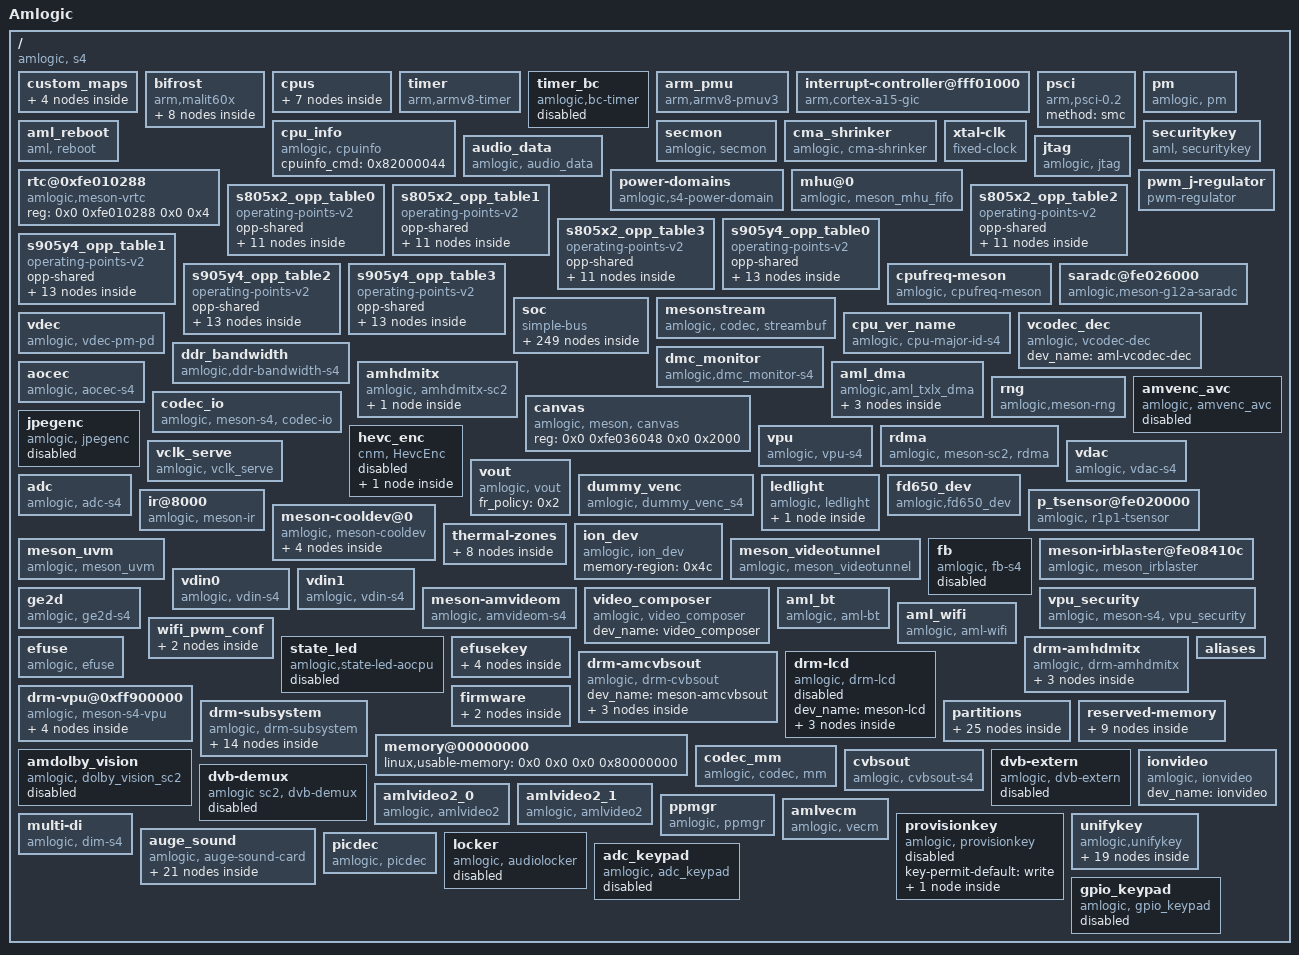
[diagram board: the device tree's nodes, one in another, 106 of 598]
/dts-v1/;

/ {
	model = "Amlogic";
	amlogic-dt-id = "s4_s905w2_2g";
	compatible = "amlogic, s4";
	interrupt-parent = <0x1>;
	#address-cells = <0x2>;
	#size-cells = <0x2>;

	custom_maps {
		mapnum = <0x4>;
		map0 = <0x2>;
		map1 = <0x3>;
		map2 = <0x4>;
		map3 = <0x5>;
		phandle = <0x46>;

		map_0 {
			mapname = "amlogic-remote-1";
			customcode = <0x4040>;
			release_delay = <0x50>;
			size = <0x18>;
			keymap = <0xb 0x10002 0x20003 0x30004 0x40005 0x50006 0x60007 0x70008 0x80009 0x9000a 0xb0067 0xe006c 0x100069 0x11006a 0xd0061 0x42009e 0x45008b 0x180073 0x170072 0x530077 0x4d0074 0x430071 0x1a0066 0x4700d9>;
			phandle = <0x2>;
		};

		map_1 {
			mapname = "amlogic-remote-2";
			customcode = <0xfe01>;
			release_delay = <0x50>;
			size = <0x35>;
			keymap = <0x10002 0x20003 0x30004 0x40005 0x50006 0x60007 0x70008 0x80009 0x9000a 0xa000b 0x1f01d2 0x15008b 0x16000f 0xc0192 0xd0193 0xe0073 0xf0072 0x110066 0x1c006a 0x1b0069 0x190067 0x1a006c 0x1d001c 0x170071 0x4900db 0x43009e 0x1201d5 0x1401d6 0x1801d7 0x590166 0x5a00a6 0x100074 0x4200a5 0x4400a3 0x1e00a8 0x4b00d0 0x5800a4 0x460082 0x400083 0x380046 0x5701d0 0x5b01d1 0x54018e 0x4c018f 0x4e0190 0x550191 0x5300ed 0x5200ee 0x3900d4 0x4100d5 0xb00d6 0xd8 0x1300d9>;
			phandle = <0x3>;
		};

		map_2 {
			mapname = "amlogic-remote-3";
			customcode = <0xbd02>;
			release_delay = <0x50>;
			size = <0x11>;
			keymap = <0xca0067 0xd2006c 0x990069 0xc1006a 0xce0061 0x450074 0xc50085 0x800071 0xd0000f 0xd6007d 0x950066 0xdd0068 0x8c006d 0x890083 0x9c0082 0x9a0078 0xcd0079>;
			phandle = <0x4>;
		};

		map_3 {
			mapname = "amlogic-remote-4";
			customcode = <0x7788>;
			release_delay = <0x50>;
			size = <0x26>;
			keymap = <0x10002 0x20003 0x30004 0x40005 0x50006 0x60007 0x70008 0x80009 0x9000a 0xa000b 0x5801d7 0x290166 0x74009c 0x4600d9 0xf008d 0x150067 0x16006c 0x170069 0x18006a 0x19001c 0x470066 0x48009e 0x32008a 0x210074 0x6001d2 0x250071 0x230073 0x240072 0x6300bb 0x6400bc 0x6700bd 0x6800be 0x330192 0x340193 0x4b018e 0x4a018f 0x490190 0x4c0191>;
			phandle = <0x5>;
		};
	};

	bifrost {
		compatible = "arm,malit60x", "arm,malit6xx", "arm,mali-midgard";
		#cooling-cells = <0x2>;
		reg = <0x0 0xfe400000 0x0 0x4000 0x0 0xfe002000 0x0 0x1000 0x0 0xff800000 0x0 0x1000 0x0 0xff63c000 0x0 0x1000 0x0 0xfe002000 0x0 0x1000>;
		interrupt-parent = <0x1>;
		interrupts = <0x0 0x90 0x4 0x0 0x91 0x4 0x0 0x92 0x4>;
		interrupt-names = "GPU", "MMU", "JOB";
		num_of_pp = <0x2>;
		sc_mpp = <0x1>;
		tbl = <0x6 0x7 0x8 0x9 0xa 0xa>;
		clk_cntl_reg = <0x57>;
		clocks = <0xb 0x91>;
		clock-names = "gpu_mux";
		assigned-clocks = <0xb 0x8b 0xb 0x8d 0xb 0x91>;
		assigned-clock-parents = <0xb 0xf 0x0 0xb 0x8d>;
		assigned-clock-rates = <0x0 0x1dcd6500 0x0>;
		phandle = <0x4b>;

		clk125_cfg {
			clk_freq = <0x7735940>;
			clk_parent = "fclk_div4";
			clkp_freq = <0x1dcd6500>;
			clk_reg = <0xa03>;
			voltage = <0x47e>;
			keep_count = <0x5>;
			threshold = <0x1e 0x78>;
		};

		dvfs250_cfg {
			clk_freq = <0xee6b280>;
			clk_parent = "fclk_div4";
			clkp_freq = <0x1dcd6500>;
			clk_reg = <0xa01>;
			voltage = <0x47e>;
			keep_count = <0x5>;
			threshold = <0x0 0x4c>;
		};

		dvfs285_cfg {
			clk_freq = <0x1107a76d>;
			clk_parent = "fclk_div7";
			clkp_freq = <0x1107a76d>;
			clk_reg = <0xe00>;
			voltage = <0x47e>;
			keep_count = <0x5>;
			threshold = <0x0 0x4c>;
			phandle = <0x6>;
		};

		dvfs400_cfg {
			clk_freq = <0x17d78400>;
			clk_parent = "fclk_div5";
			clkp_freq = <0x17d78400>;
			clk_reg = <0xc00>;
			voltage = <0x47e>;
			keep_count = <0x5>;
			threshold = <0x98 0xcf>;
			phandle = <0x7>;
		};

		dvfs500_cfg {
			clk_freq = <0x1dcd6500>;
			clk_parent = "fclk_div4";
			clkp_freq = <0x1dcd6500>;
			clk_reg = <0xa00>;
			voltage = <0x47e>;
			keep_count = <0x5>;
			threshold = <0x26 0xc2>;
			phandle = <0x8>;
		};

		dvfs666_cfg {
			clk_freq = <0x27bc86aa>;
			clk_parent = "fclk_div3";
			clkp_freq = <0x27bc86aa>;
			clk_reg = <0x800>;
			voltage = <0x47e>;
			keep_count = <0x5>;
			threshold = <0x96 0xcb>;
			phandle = <0x9>;
		};

		dvfs800_cfg {
			clk_freq = <0x2faf0800>;
			clk_parent = "fclk_div2p5";
			clkp_freq = <0x2faf0800>;
			clk_reg = <0x600>;
			voltage = <0x47e>;
			keep_count = <0x5>;
			threshold = <0xe6 0xff>;
			phandle = <0xa>;
		};

		dvfs850_cfg {
			clk_freq = <0x326cef80>;
			clk_parent = "gp0_pll";
			clkp_freq = <0x326cef80>;
			clk_reg = <0x200>;
			voltage = <0x47e>;
			keep_count = <0x5>;
			threshold = <0x9c 0xff>;
		};
	};

	cpus {
		#address-cells = <0x2>;
		#size-cells = <0x0>;

		cpu@0 {
			device_type = "cpu";
			compatible = "arm,cortex-a55", "arm,armv8";
			reg = <0x0 0x0>;
			enable-method = "psci";
			cpu-idle-states = <0xc 0xd>;
			dynamic-power-coefficient = <0xe6>;
			#cooling-cells = <0x2>;
			clocks = <0xb 0x1b 0xb 0x1a 0xb 0x3>;
			clock-names = "core_clk", "low_freq_clk_parent", "high_freq_clk_parent";
			cpu-supply = <0xe>;
			voltage-tolerance = <0x0>;
			clock-latency = <0xc350>;
			multi_tables_available;
			operating-points-v2 = <0xf 0x10 0x11 0x12>;
			phandle = <0x4a>;
		};

		cpu@1 {
			device_type = "cpu";
			compatible = "arm,cortex-a55", "arm,armv8";
			reg = <0x0 0x1>;
			enable-method = "psci";
			cpu-idle-states = <0xc 0xd>;
			dynamic-power-coefficient = <0xe6>;
			#cooling-cells = <0x2>;
			clocks = <0xb 0x1b 0xb 0x1a 0xb 0x3>;
			clock-names = "core_clk", "low_freq_clk_parent", "high_freq_clk_parent";
			cpu-supply = <0xe>;
			voltage-tolerance = <0x0>;
			clock-latency = <0xc350>;
			multi_tables_available;
			operating-points-v2 = <0xf 0x10 0x11 0x12>;
		};

		cpu@2 {
			device_type = "cpu";
			compatible = "arm,cortex-a55", "arm,armv8";
			reg = <0x0 0x2>;
			enable-method = "psci";
			cpu-idle-states = <0xc 0xd>;
			dynamic-power-coefficient = <0xe6>;
			#cooling-cells = <0x2>;
			clocks = <0xb 0x1b 0xb 0x1a 0xb 0x3>;
			clock-names = "core_clk", "low_freq_clk_parent", "high_freq_clk_parent";
			cpu-supply = <0xe>;
			voltage-tolerance = <0x0>;
			clock-latency = <0xc350>;
			multi_tables_available;
			operating-points-v2 = <0xf 0x10 0x11 0x12>;
		};

		cpu@3 {
			device_type = "cpu";
			compatible = "arm,cortex-a55", "arm,armv8";
			reg = <0x0 0x3>;
			enable-method = "psci";
			cpu-idle-states = <0xc 0xd>;
			dynamic-power-coefficient = <0xe6>;
			#cooling-cells = <0x2>;
			clocks = <0xb 0x1b 0xb 0x1a 0xb 0x3>;
			clock-names = "core_clk", "low_freq_clk_parent", "high_freq_clk_parent";
			cpu-supply = <0xe>;
			voltage-tolerance = <0x0>;
			clock-latency = <0xc350>;
			multi_tables_available;
			operating-points-v2 = <0xf 0x10 0x11 0x12>;
		};

		idle-states {
			entry-method = "arm,psci-0.2";

			cpu-sleep-0 {
				compatible = "arm,idle-state";
				arm,psci-suspend-param = <0x10000>;
				local-timer-stop;
				entry-latency-us = <0xfa0>;
				exit-latency-us = <0x1388>;
				min-residency-us = <0x2710>;
				phandle = <0xc>;
			};

			system-sleep-0 {
				compatible = "arm,idle-state";
				arm,psci-suspend-param = <0x0>;
				entry-latency-us = <0x3fffffff>;
				exit-latency-us = <0x40000000>;
				min-residency-us = <0xffffffff>;
				phandle = <0xd>;
			};
		};
	};

	timer {
		compatible = "arm,armv8-timer";
		interrupts = <0x1 0xd 0xff08 0x1 0xe 0xff08 0x1 0xb 0xff08 0x1 0xa 0xff08>;
	};

	timer_bc {
		compatible = "amlogic,bc-timer";
		status = "disabled";
		reg = <0x0 0xfe0100d8 0x0 0x4 0x0 0xfe0100dc 0x0 0x4>;
		timer_name = "Meson TimerD";
		clockevent-rating = <0x12c>;
		clockevent-shift = <0x14>;
		clockevent-features = <0x23>;
		interrupts = <0x0 0x3 0x1>;
		bit_enable = <0x7>;
		bit_mode = <0x6>;
		bit_resolution = <0x0>;
		resolution_1us = <0x1>;
		min_delta_ns = <0xa>;
	};

	arm_pmu {
		compatible = "arm,armv8-pmuv3";
		private-interrupts;
		interrupts = <0x0 0xe9 0x4 0x0 0xea 0x4 0x0 0xeb 0x4 0x0 0xec 0x4>;
		reg = <0x0 0xff634680 0x0 0x4>;
		cpumasks = <0xf>;
		relax-timer-ns = <0x989680>;
		max-wait-cnt = <0x2710>;
	};

	interrupt-controller@fff01000 {
		compatible = "arm,cortex-a15-gic", "arm,cortex-a9-gic";
		#interrupt-cells = <0x3>;
		#address-cells = <0x0>;
		interrupt-controller;
		reg = <0x0 0xfff01000 0x0 0x1000 0x0 0xfff02000 0x0 0x100>;
		interrupts = <0x1 0x9 0xf04>;
		phandle = <0x1>;
	};

	psci {
		compatible = "arm,psci-0.2";
		method = "smc";
	};

	pm {
		compatible = "amlogic, pm";
		status = "okay";
		device_name = "aml_pm";
		reg = <0x0 0xfe010288 0x0 0x4 0x0 0xfe0102dc 0x0 0x4>;
	};

	cpu_info {
		compatible = "amlogic, cpuinfo";
		status = "okay";
		cpuinfo_cmd = <0x82000044>;
	};

	aml_reboot {
		compatible = "aml, reboot";
		sys_reset = <0x84000009>;
		sys_poweroff = <0x84000008>;
		dis_nb_cpus_in_shutdown;
	};

	secmon {
		compatible = "amlogic, secmon";
		memory-region = <0x13>;
		in_base_func = <0x82000020>;
		out_base_func = <0x82000021>;
		reserve_mem_size = <0x3300000>;
	};

	cma_shrinker {
		compatible = "amlogic, cma-shrinker";
		status = "okay";
		adj = <0x0 0x64 0xc8 0xfa 0x384 0x3b6>;
		free = <0x1e00 0x5ee0 0x6f70 0x7f58 0x8000 0x8f10>;
	};

	securitykey {
		compatible = "aml, securitykey";
		storage_query = <0x82000060>;
		storage_read = <0x82000061>;
		storage_write = <0x82000062>;
		storage_tell = <0x82000063>;
		storage_verify = <0x82000064>;
		storage_status = <0x82000065>;
		storage_list = <0x82000067>;
		storage_remove = <0x82000068>;
		storage_in_func = <0x82000023>;
		storage_out_func = <0x82000024>;
		storage_block_func = <0x82000025>;
		storage_size_func = <0x82000027>;
		storage_set_enctype = <0x8200006a>;
		storage_get_enctype = <0x8200006b>;
		storage_version = <0x8200006c>;
	};

	xtal-clk {
		compatible = "fixed-clock";
		clock-frequency = <0x16e3600>;
		clock-output-names = "xtal";
		#clock-cells = <0x0>;
		phandle = <0x18>;
	};

	rtc@0xfe010288 {
		compatible = "amlogic,meson-vrtc";
		reg = <0x0 0xfe010288 0x0 0x4>;
	};

	audio_data {
		compatible = "amlogic, audio_data";
		mem_in_base_cmd = <0x82000020>;
		query_licence_cmd = <0x82000050>;
		status = "okay";
	};

	power-domains {
		compatible = "amlogic,s4-power-domain";
		#power-domain-cells = <0x1>;
		status = "okay";
		phandle = <0x25>;
	};

	jtag {
		compatible = "amlogic, jtag";
		status = "okay";
		select = "disable";
		pinctrl-names = "jtag_a_pins", "jtag_b_pins";
		pinctrl-0 = <0x14>;
		pinctrl-1 = <0x15>;
	};

	mhu@0 {
		status = "okay";
		compatible = "amlogic, meson_mhu_fifo";
		reg = <0x0 0xfe006000 0x0 0x800 0x0 0xfe006800 0x0 0x800 0x0 0xfe0070c0 0x0 0x40 0x0 0xfe007100 0x0 0x40 0x0 0xfe007140 0x0 0x40 0x0 0xfe007020 0x0 0x40>;
		interrupts = <0x0 0xf8 0x1>;
		mbox-irqctlr = <0x0>;
		mbox-nums = <0x2>;
		mbox-names = "ao_dev", "ap_to_ao";
		mboxes = <0x16 0x0 0x16 0x1>;
		mbox-id = <0x2 0x3>;
		#mbox-cells = <0x1>;
		phandle = <0x16>;
	};

	pwm_j-regulator {
		compatible = "pwm-regulator";
		pwms = <0x17 0x1 0x5dc 0x0>;
		regulator-name = "vddcpu0";
		regulator-min-microvolt = <0xa8368>;
		regulator-max-microvolt = <0x1001a8>;
		regulator-always-on;
		max-duty-cycle = <0x5dc>;
		voltage-table = <0x1001a8 0x0 0xfda98 0x3 0xfb388 0x6 0xf8c78 0x9 0xf6568 0xc 0xf3e58 0xe 0xf1748 0x11 0xef038 0x14 0xec928 0x17 0xea218 0x1a 0xe7b08 0x1d 0xe53f8 0x1f 0xe2ce8 0x22 0xe05d8 0x25 0xddec8 0x28 0xdb7b8 0x2b 0xd90a8 0x2d 0xd6998 0x30 0xd4288 0x33 0xd1b78 0x36 0xcf468 0x38 0xccd58 0x3b 0xca648 0x3e 0xc7f38 0x41 0xc5828 0x44 0xc3118 0x46 0xc0a08 0x49 0xbe2f8 0x4c 0xbbbe8 0x4f 0xb94d8 0x51 0xb6dc8 0x54 0xb46b8 0x57 0xb1fa8 0x59 0xaf898 0x5c 0xad188 0x5f 0xaaa78 0x62 0xa8368 0x64>;
		status = "okay";
		phandle = <0xe>;
	};

	s805x2_opp_table0 {
		compatible = "operating-points-v2";
		status = "okay";
		opp-shared;
		phandle = <0xf>;

		opp00 {
			opp-hz = <0x0 0x5f5e100>;
			opp-microvolt = <0xbbbe8>;
		};

		opp01 {
			opp-hz = <0x0 0xee6b280>;
			opp-microvolt = <0xbbbe8>;
		};

		opp02 {
			opp-hz = <0x0 0x1dcd6500>;
			opp-microvolt = <0xbbbe8>;
		};

		opp03 {
			opp-hz = <0x0 0x27b25a80>;
			opp-microvolt = <0xbbbe8>;
		};

		opp04 {
			opp-hz = <0x0 0x3b9aca00>;
			opp-microvolt = <0xbbbe8>;
		};

		opp05 {
			opp-hz = <0x0 0x47868c00>;
			opp-microvolt = <0xbbbe8>;
		};

		opp06 {
			opp-hz = <0x0 0x53af5700>;
			opp-microvolt = <0xc3118>;
		};

		opp07 {
			opp-hz = <0x0 0x59682f00>;
			opp-microvolt = <0xca648>;
		};

		opp08 {
			opp-hz = <0x0 0x5fd82200>;
			opp-microvolt = <0xd4288>;
		};

		opp09 {
			opp-hz = <0x0 0x6590fa00>;
			opp-microvolt = <0xddec8>;
		};

		opp10 {
			opp-hz = <0x0 0x6b49d200>;
			opp-microvolt = <0xf6568>;
		};
	};

	s805x2_opp_table1 {
		compatible = "operating-points-v2";
		status = "okay";
		opp-shared;
		phandle = <0x10>;

		opp00 {
			opp-hz = <0x0 0x5f5e100>;
			opp-microvolt = <0xbbbe8>;
		};

		opp01 {
			opp-hz = <0x0 0xee6b280>;
			opp-microvolt = <0xbbbe8>;
		};

		opp02 {
			opp-hz = <0x0 0x1dcd6500>;
			opp-microvolt = <0xbbbe8>;
		};

		opp03 {
			opp-hz = <0x0 0x27b25a80>;
			opp-microvolt = <0xbbbe8>;
		};

		opp04 {
			opp-hz = <0x0 0x3b9aca00>;
			opp-microvolt = <0xbbbe8>;
		};

		opp05 {
			opp-hz = <0x0 0x47868c00>;
			opp-microvolt = <0xbbbe8>;
		};

		opp06 {
			opp-hz = <0x0 0x53af5700>;
			opp-microvolt = <0xc3118>;
		};

		opp07 {
			opp-hz = <0x0 0x59682f00>;
			opp-microvolt = <0xca648>;
		};

		opp08 {
			opp-hz = <0x0 0x5fd82200>;
			opp-microvolt = <0xd4288>;
		};

		opp09 {
			opp-hz = <0x0 0x6590fa00>;
			opp-microvolt = <0xddec8>;
		};

		opp10 {
			opp-hz = <0x0 0x6b49d200>;
			opp-microvolt = <0xf6568>;
		};
	};

	s805x2_opp_table2 {
		compatible = "operating-points-v2";
		status = "okay";
		opp-shared;
		phandle = <0x11>;

		opp00 {
			opp-hz = <0x0 0x5f5e100>;
			opp-microvolt = <0xb94d8>;
		};

		opp01 {
			opp-hz = <0x0 0xee6b280>;
			opp-microvolt = <0xb94d8>;
		};

		opp02 {
			opp-hz = <0x0 0x1dcd6500>;
			opp-microvolt = <0xb94d8>;
		};

		opp03 {
			opp-hz = <0x0 0x27b25a80>;
			opp-microvolt = <0xb94d8>;
		};

		opp04 {
			opp-hz = <0x0 0x3b9aca00>;
			opp-microvolt = <0xb94d8>;
		};

		opp05 {
			opp-hz = <0x0 0x47868c00>;
			opp-microvolt = <0xb94d8>;
		};

		opp06 {
			opp-hz = <0x0 0x53af5700>;
			opp-microvolt = <0xb94d8>;
		};

		opp07 {
			opp-hz = <0x0 0x59682f00>;
			opp-microvolt = <0xbbbe8>;
		};

		opp08 {
			opp-hz = <0x0 0x5fd82200>;
			opp-microvolt = <0xc3118>;
		};

		opp09 {
			opp-hz = <0x0 0x6590fa00>;
			opp-microvolt = <0xca648>;
		};

		opp10 {
			opp-hz = <0x0 0x6b49d200>;
			opp-microvolt = <0xf3e58>;
		};
	};

	s805x2_opp_table3 {
		compatible = "operating-points-v2";
		status = "okay";
		opp-shared;
		phandle = <0x12>;

		opp00 {
			opp-hz = <0x0 0x5f5e100>;
			opp-microvolt = <0xb94d8>;
		};

		opp01 {
			opp-hz = <0x0 0xee6b280>;
			opp-microvolt = <0xb94d8>;
		};

		opp02 {
			opp-hz = <0x0 0x1dcd6500>;
			opp-microvolt = <0xb94d8>;
		};

		opp03 {
			opp-hz = <0x0 0x27b25a80>;
			opp-microvolt = <0xb94d8>;
		};

		opp04 {
			opp-hz = <0x0 0x3b9aca00>;
			opp-microvolt = <0xb94d8>;
		};

		opp05 {
			opp-hz = <0x0 0x47868c00>;
			opp-microvolt = <0xb94d8>;
		};

		opp06 {
			opp-hz = <0x0 0x53af5700>;
			opp-microvolt = <0xb94d8>;
		};

		opp07 {
			opp-hz = <0x0 0x59682f00>;
			opp-microvolt = <0xb94d8>;
		};

		opp08 {
			opp-hz = <0x0 0x5fd82200>;
			opp-microvolt = <0xbbbe8>;
		};

		opp09 {
			opp-hz = <0x0 0x6590fa00>;
			opp-microvolt = <0xc5828>;
		};

		opp10 {
			opp-hz = <0x0 0x6b49d200>;
			opp-microvolt = <0xe53f8>;
		};
	};

	s905y4_opp_table0 {
		compatible = "operating-points-v2";
		status = "okay";
		opp-shared;

		opp00 {
			opp-hz = <0x0 0x5f5e100>;
			opp-microvolt = <0xbbbe8>;
		};

		opp01 {
			opp-hz = <0x0 0xee6b280>;
			opp-microvolt = <0xbbbe8>;
		};

		opp02 {
			opp-hz = <0x0 0x1dcd6500>;
			opp-microvolt = <0xbbbe8>;
		};

		opp03 {
			opp-hz = <0x0 0x27b25a80>;
			opp-microvolt = <0xbbbe8>;
		};

		opp04 {
			opp-hz = <0x0 0x3b9aca00>;
			opp-microvolt = <0xbbbe8>;
		};

		opp05 {
			opp-hz = <0x0 0x47868c00>;
			opp-microvolt = <0xbbbe8>;
		};

		opp06 {
			opp-hz = <0x0 0x53af5700>;
			opp-microvolt = <0xc3118>;
		};

		opp07 {
			opp-hz = <0x0 0x59682f00>;
			opp-microvolt = <0xca648>;
		};

		opp08 {
			opp-hz = <0x0 0x5fd82200>;
			opp-microvolt = <0xd4288>;
		};

		opp09 {
			opp-hz = <0x0 0x6590fa00>;
			opp-microvolt = <0xddec8>;
		};

		opp10 {
			opp-hz = <0x0 0x6b49d200>;
			opp-microvolt = <0xea218>;
		};

		opp11 {
			opp-hz = <0x0 0x71b9c500>;
			opp-microvolt = <0xef038>;
		};

		opp12 {
			opp-hz = <0x0 0x77729d00>;
			opp-microvolt = <0xf6568>;
		};
	};

	s905y4_opp_table1 {
		compatible = "operating-points-v2";
		status = "okay";
		opp-shared;

		opp00 {
			opp-hz = <0x0 0x5f5e100>;
			opp-microvolt = <0xbbbe8>;
		};

		opp01 {
			opp-hz = <0x0 0xee6b280>;
			opp-microvolt = <0xbbbe8>;
		};

		opp02 {
			opp-hz = <0x0 0x1dcd6500>;
			opp-microvolt = <0xbbbe8>;
		};

		opp03 {
			opp-hz = <0x0 0x27b25a80>;
			opp-microvolt = <0xbbbe8>;
		};

		opp04 {
			opp-hz = <0x0 0x3b9aca00>;
			opp-microvolt = <0xbbbe8>;
		};

		opp05 {
			opp-hz = <0x0 0x47868c00>;
			opp-microvolt = <0xbbbe8>;
		};

		opp06 {
			opp-hz = <0x0 0x53af5700>;
			opp-microvolt = <0xc3118>;
		};

		opp07 {
			opp-hz = <0x0 0x59682f00>;
			opp-microvolt = <0xca648>;
		};

		opp08 {
			opp-hz = <0x0 0x5fd82200>;
			opp-microvolt = <0xd4288>;
		};

		opp09 {
			opp-hz = <0x0 0x6590fa00>;
			opp-microvolt = <0xddec8>;
		};

		opp10 {
			opp-hz = <0x0 0x6b49d200>;
			opp-microvolt = <0xea218>;
		};

		opp11 {
			opp-hz = <0x0 0x71b9c500>;
			opp-microvolt = <0xef038>;
		};

		opp12 {
			opp-hz = <0x0 0x77729d00>;
			opp-microvolt = <0xf6568>;
		};
	};

	s905y4_opp_table2 {
		compatible = "operating-points-v2";
		status = "okay";
		opp-shared;

		opp00 {
			opp-hz = <0x0 0x5f5e100>;
			opp-microvolt = <0xb94d8>;
		};

		opp01 {
			opp-hz = <0x0 0xee6b280>;
			opp-microvolt = <0xb94d8>;
		};

		opp02 {
			opp-hz = <0x0 0x1dcd6500>;
			opp-microvolt = <0xb94d8>;
		};

		opp03 {
			opp-hz = <0x0 0x27b25a80>;
			opp-microvolt = <0xb94d8>;
		};

		opp04 {
			opp-hz = <0x0 0x3b9aca00>;
			opp-microvolt = <0xb94d8>;
		};

		opp05 {
			opp-hz = <0x0 0x47868c00>;
			opp-microvolt = <0xb94d8>;
		};

		opp06 {
			opp-hz = <0x0 0x53af5700>;
			opp-microvolt = <0xb94d8>;
		};

		opp07 {
			opp-hz = <0x0 0x59682f00>;
			opp-microvolt = <0xbbbe8>;
		};

		opp08 {
			opp-hz = <0x0 0x5fd82200>;
			opp-microvolt = <0xc3118>;
		};

		opp09 {
			opp-hz = <0x0 0x6590fa00>;
			opp-microvolt = <0xca648>;
		};

		opp10 {
			opp-hz = <0x0 0x6b49d200>;
			opp-microvolt = <0xe2ce8>;
		};

		opp11 {
			opp-hz = <0x0 0x71b9c500>;
			opp-microvolt = <0xea218>;
		};

		opp12 {
			opp-hz = <0x0 0x77729d00>;
			opp-microvolt = <0xf3e58>;
		};
	};

	s905y4_opp_table3 {
		compatible = "operating-points-v2";
		status = "okay";
		opp-shared;

		opp00 {
			opp-hz = <0x0 0x5f5e100>;
			opp-microvolt = <0xb94d8>;
		};

		opp01 {
			opp-hz = <0x0 0xee6b280>;
			opp-microvolt = <0xb94d8>;
		};

		opp02 {
			opp-hz = <0x0 0x1dcd6500>;
			opp-microvolt = <0xb94d8>;
		};

		opp03 {
			opp-hz = <0x0 0x27b25a80>;
			opp-microvolt = <0xb94d8>;
		};

		opp04 {
			opp-hz = <0x0 0x3b9aca00>;
			opp-microvolt = <0xb94d8>;
		};

		opp05 {
			opp-hz = <0x0 0x47868c00>;
			opp-microvolt = <0xb94d8>;
		};

		opp06 {
			opp-hz = <0x0 0x53af5700>;
			opp-microvolt = <0xb94d8>;
		};

		opp07 {
			opp-hz = <0x0 0x59682f00>;
			opp-microvolt = <0xb94d8>;
		};

		opp08 {
			opp-hz = <0x0 0x5fd82200>;
			opp-microvolt = <0xbbbe8>;
		};

		opp09 {
			opp-hz = <0x0 0x6590fa00>;
			opp-microvolt = <0xc5828>;
		};

		opp10 {
			opp-hz = <0x0 0x6b49d200>;
			opp-microvolt = <0xd90a8>;
		};

		opp11 {
			opp-hz = <0x0 0x71b9c500>;
			opp-microvolt = <0xddec8>;
		};

		opp12 {
			opp-hz = <0x0 0x77729d00>;
			opp-microvolt = <0xe53f8>;
		};
	};

	cpufreq-meson {
		compatible = "amlogic, cpufreq-meson";
		status = "okay";
	};

	saradc@fe026000 {
		compatible = "amlogic,meson-g12a-saradc", "amlogic,meson-saradc";
		status = "okay";
		#io-channel-cells = <0x1>;
		clocks = <0x18 0xb 0x136 0xb 0x104 0xb 0x102>;
		clock-names = "clkin", "core", "adc_clk", "adc_sel";
		interrupts = <0x0 0xb5 0x1>;
		reg = <0x0 0xfe026000 0x0 0x48>;
		phandle = <0xa1>;
	};

	soc {
		compatible = "simple-bus";
		#address-cells = <0x2>;
		#size-cells = <0x2>;
		ranges;

		apb4@fe000000 {
			compatible = "simple-bus";
			reg = <0x0 0xfe000000 0x0 0x480000>;
			#address-cells = <0x2>;
			#size-cells = <0x2>;
			ranges = <0x0 0x0 0x0 0xfe000000 0x0 0x480000>;

			clock-controller {
				compatible = "amlogic,s4-clkc";
				#clock-cells = <0x1>;
				reg = <0x0 0x0 0x0 0x49c 0x0 0x8000 0x0 0x348 0x0 0xe140 0x0 0x24>;
				reg-names = "basic", "pll", "cpu_clk";
				clocks = <0x18>;
				clock-names = "xtal";
				status = "okay";
				phandle = <0xb>;
			};

			meson_clk_msr@48000 {
				compatible = "amlogic,meson-s4-clk-measure";
				reg = <0x0 0x48000 0x0 0x1c>;
			};

			watchdog@2100 {
				compatible = "amlogic,meson-sc2-wdt";
				status = "okay";
				amlogic,feed_watchdog_mode = <0x1>;
				reg = <0x0 0x2100 0x0 0x10>;
				clocks = <0x18>;
			};

			pinctrl@4000 {
				compatible = "amlogic,meson-s4-periphs-pinctrl";
				#address-cells = <0x2>;
				#size-cells = <0x2>;
				ranges;
				phandle = <0x19>;

				bank@4000 {
					reg = <0x0 0x4000 0x0 0x4c 0x0 0x40c0 0x0 0x220>;
					reg-names = "mux", "gpio";
					gpio-controller;
					#gpio-cells = <0x2>;
					gpio-ranges = <0x19 0x0 0x0 0x52>;
					phandle = <0x1b>;
				};

				i2c0_pins1 {

					mux {
						groups = "i2c0_sda", "i2c0_scl";
						function = "i2c0";
						drive-strength-microamp = <0xbb8>;
						bias-disable;
					};
				};

				i2c1_pins1 {

					mux {
						groups = "i2c1_sda_c", "i2c1_scl_c";
						function = "i2c1";
						drive-strength-microamp = <0xbb8>;
						bias-disable;
					};
				};

				i2c1_pins2 {
					phandle = <0x1e>;

					mux {
						groups = "i2c1_sda_d", "i2c1_scl_d";
						function = "i2c1";
						drive-strength-microamp = <0xbb8>;
						bias-disable;
					};
				};

				i2c1_pins3 {

					mux {
						groups = "i2c1_sda_h", "i2c1_scl_h";
						function = "i2c1";
						drive-strength-microamp = <0xbb8>;
						bias-disable;
					};
				};

				i2c1_pins4 {

					mux {
						groups = "i2c1_sda_x", "i2c1_scl_x";
						function = "i2c1";
						drive-strength-microamp = <0xbb8>;
						bias-disable;
					};
				};

				i2c2_pins1 {

					mux {
						groups = "i2c2_sda_d", "i2c2_scl_d";
						function = "i2c2";
						drive-strength-microamp = <0xbb8>;
						bias-disable;
					};
				};

				i2c2_pins2 {

					mux {
						groups = "i2c2_sda_h8", "i2c2_scl_h9";
						function = "i2c2";
						drive-strength-microamp = <0xbb8>;
						bias-disable;
					};
				};

				i2c2_pins3 {

					mux {
						groups = "i2c2_sda_h0", "i2c2_scl_h1";
						function = "i2c2";
						drive-strength-microamp = <0xbb8>;
						bias-disable;
					};
				};

				i2c3_pins1 {

					mux {
						groups = "i2c3_sda_x", "i2c3_scl_x";
						function = "i2c3";
						drive-strength-microamp = <0xbb8>;
						bias-disable;
					};
				};

				i2c3_pins2 {
					phandle = <0x1f>;

					mux {
						groups = "i2c3_sda_z", "i2c3_scl_z";
						function = "i2c3";
						drive-strength-microamp = <0xbb8>;
						bias-disable;
					};
				};

				i2c4_pins1 {

					mux {
						groups = "i2c4_sda_c", "i2c4_scl_c";
						function = "i2c4";
						drive-strength-microamp = <0xbb8>;
						bias-disable;
					};
				};

				i2c4_pins2 {

					mux {
						groups = "i2c4_sda_d", "i2c4_scl_d";
						function = "i2c4";
						drive-strength-microamp = <0xbb8>;
						bias-disable;
					};
				};

				i2c4_pins3 {
					phandle = <0x20>;

					mux {
						groups = "i2c4_sda_z", "i2c4_scl_z";
						function = "i2c4";
						drive-strength-microamp = <0xbb8>;
						bias-disable;
					};
				};

				a_uart {
					phandle = <0x3c>;

					mux {
						groups = "uart_a_tx", "uart_a_rx", "uart_a_cts", "uart_a_rts";
						function = "uart_a";
					};
				};

				c_uart {
					phandle = <0x3d>;

					mux {
						groups = "uart_c_tx", "uart_c_rx";
						function = "uart_c";
					};
				};

				d_uart1 {
					phandle = <0x3e>;

					mux {
						groups = "uart_d_tx_h", "uart_d_rx_h";
						function = "uart_d";
					};
				};

				d_uart2 {

					mux {
						groups = "uart_d_tx_z", "uart_d_rx_z";
						function = "uart_d";
					};
				};

				e_uart1 {
					phandle = <0x3f>;

					mux {
						groups = "uart_e_tx_h", "uart_e_rx_h";
						function = "uart_e";
					};
				};

				e_uart2 {

					mux {
						groups = "uart_e_tx_z11", "uart_e_rx_z12";
						function = "uart_e";
					};
				};

				e_uart3 {

					mux {
						groups = "uart_e_tx_z8", "uart_e_rx_z9";
						function = "uart_e";
					};
				};

				emmc_pins {
					phandle = <0x2e>;

					mux-0 {
						groups = "emmc_nand_d0", "emmc_nand_d1", "emmc_nand_d2", "emmc_nand_d3", "emmc_nand_d4", "emmc_nand_d5", "emmc_nand_d6", "emmc_nand_d7", "emmc_cmd";
						function = "emmc";
						bias-pull-up;
						drive-strength-microamp = <0xfa0>;
					};

					mux-1 {
						groups = "emmc_clk";
						function = "emmc";
						bias-pull-up;
						drive-strength-microamp = <0xfa0>;
					};
				};

				emmc_ds_pins {
					phandle = <0x2f>;

					mux {
						groups = "emmc_nand_ds";
						function = "emmc";
						bias-pull-down;
						drive-strength-microamp = <0xfa0>;
					};
				};

				emmc_clk_gate_pins {
					phandle = <0x30>;

					mux {
						groups = "GPIOB_8";
						function = "gpio_periphs";
						bias-pull-down;
						drive-strength-microamp = <0xfa0>;
					};
				};

				all_nand_pins {
					phandle = <0x39>;

					mux {
						groups = "emmc_nand_d0", "emmc_nand_d1", "emmc_nand_d2", "emmc_nand_d3", "emmc_nand_d4", "emmc_nand_d5", "emmc_nand_d6", "emmc_nand_d7", "nand_ce0", "nand_ale", "nand_cle", "nand_wen_clk", "nand_ren_wr";
						function = "nand";
						input-enable;
					};
				};

				nand_cs {
					phandle = <0x3a>;

					mux {
						groups = "nand_ce0";
						function = "nand";
					};
				};

				sd_to_ao_uart_clr_pins {
					phandle = <0x34>;

					mux {
						groups = "GPIOD_0", "GPIOD_1";
						function = "gpio_periphs";
					};
				};

				sdcard_pins {
					phandle = <0x31>;

					mux {
						groups = "sdcard_d0_c", "sdcard_d1_c", "sdcard_d2_c", "sdcard_d3_c", "sdcard_clk_c", "sdcard_cmd_c";
						function = "sdcard";
						bias-pull-up;
						drive-strength-microamp = <0xfa0>;
					};
				};

				ao_to_sd_uart_pins {
					phandle = <0x35>;

					mux {
						groups = "uart_b_tx_c", "uart_b_rx_c";
						function = "uart_b";
						bias-pull-up;
						input-enable;
					};
				};

				ao_uart_pins {
					phandle = <0x36>;

					mux {
						groups = "uart_b_tx_d", "uart_b_rx_d";
						function = "uart_b";
						bias-pull-up;
						input-enable;
					};
				};

				sd_clr_all_pins {

					mux {
						groups = "GPIOC_0", "GPIOC_1", "GPIOC_2", "GPIOC_3", "GPIOC_5";
						function = "gpio_periphs";
						output-high;
					};

					mux1 {
						groups = "GPIOC_4";
						function = "gpio_periphs";
						output-low;
					};
				};

				sd_clr_noall_pins {

					mux {
						groups = "GPIOC_0", "GPIOC_1", "GPIOC_4", "GPIOC_5";
						function = "gpio_periphs";
						output-high;
					};
				};

				sd_1bit_pins {
					phandle = <0x33>;

					mux {
						groups = "sdcard_d0_c", "sdcard_clk_c", "sdcard_cmd_c";
						function = "sdcard";
						bias-pull-up;
						drive-strength-microamp = <0xfa0>;
					};
				};

				sdcard_clk_gate_pins {
					phandle = <0x32>;

					mux {
						groups = "GPIOC_4";
						function = "gpio_periphs";
						bias-pull-down;
						drive-strength-microamp = <0xfa0>;
					};
				};

				sd_iso7816_pins {

					mux {
						groups = "iso7816_clk_h", "iso7816_data_h";
						function = "iso7816";
						input-enable;
						bias-pull-down;
					};
				};

				sdio_pins {
					phandle = <0x37>;

					mux {
						groups = "sdio_d0", "sdio_d1", "sdio_d2", "sdio_d3", "sdio_clk", "sdio_cmd";
						function = "sdio";
						bias-pull-up;
						drive-strength-microamp = <0xfa0>;
					};
				};

				sdio_clk_gate_pins {
					phandle = <0x38>;

					mux {
						groups = "GPIOX_4";
						function = "gpio_periphs";
						bias-pull-down;
						drive-strength-microamp = <0xfa0>;
					};
				};

				hdmitx_hpd {
					phandle = <0x41>;

					mux {
						groups = "hdmitx_hpd_in";
						function = "hdmitx";
						bias-disable;
					};
				};

				hdmitx_hpd_gpio {

					mux {
						groups = "GPIOH_1";
						function = "gpio_periphs";
						bias-disable;
					};
				};

				hdmitx_ddc {
					phandle = <0x42>;

					mux {
						groups = "hdmitx_sda", "hdmitx_sck";
						function = "hdmitx";
						bias-disable;
						drive-strength = <0x3>;
					};
				};

				dtvdemod_if_agc_pins {

					mux {
						groups = "dtv_a_if_agc_z6", "dtv_b_if_agc";
						function = "dtv";
					};
				};

				ee_ceca {
					phandle = <0x43>;

					mux {
						groups = "ao_cec_a";
						function = "ao_cec_a";
					};
				};

				ee_cecb {
					phandle = <0x44>;

					mux {
						groups = "ao_cec_b";
						function = "ao_cec_b";
					};
				};

				jtag_a_pin {
					phandle = <0x14>;

					mux {
						groups = "jtag_1_tdi", "jtag_1_tdo", "jtag_1_clk", "jtag_1_tms";
						function = "jtag_1";
					};
				};

				jtag_b_pin {
					phandle = <0x15>;

					mux {
						groups = "jtag_2_tdi", "jtag_2_tdo", "jtag_2_clk", "jtag_2_tms";
						function = "jtag_2";
					};
				};

				pwm_a_pins {

					mux {
						groups = "pwm_a_d";
						function = "pwm_a";
					};
				};

				pwm_b_pins1 {

					mux {
						groups = "pwm_b_d";
						function = "pwm_b";
					};
				};

				pwm_b_pins2 {

					mux {
						groups = "pwm_b_x";
						function = "pwm_b";
					};
				};

				pwm_c_pins1 {

					mux {
						groups = "pwm_c_d";
						function = "pwm_c";
					};
				};

				pwm_c_pins2 {

					mux {
						groups = "pwm_c_x";
						function = "pwm_c";
					};
				};

				pwm_d_pins1 {

					mux {
						groups = "pwm_d_d";
						function = "pwm_d";
					};
				};

				pwm_d_pins2 {

					mux {
						groups = "pwm_d_h";
						function = "pwm_d";
					};
				};

				pwm_e_pins1 {
					phandle = <0x1d>;

					mux {
						groups = "pwm_e_x";
						function = "pwm_e";
						drive-strength-microamp = <0x1f4>;
					};
				};

				pwm_e_pins2 {

					mux {
						groups = "pwm_e_z";
						function = "pwm_e";
					};
				};

				pwm_f_pins1 {

					mux {
						groups = "pwm_f_x";
						function = "pwm_f";
					};
				};

				pwm_f_pins2 {

					mux {
						groups = "pwm_f_z";
						function = "pwm_f";
					};
				};

				pwm_g_pins1 {

					mux {
						groups = "pwm_g_d";
						function = "pwm_g";
					};
				};

				pwm_g_pins2 {

					mux {
						groups = "pwm_g_z";
						function = "pwm_g";
					};
				};

				pwm_h_pins {

					mux {
						groups = "pwm_h";
						function = "pwm_h";
					};
				};

				pwm_i_pins1 {

					mux {
						groups = "pwm_i_d";
						function = "pwm_i";
					};
				};

				pwm_i_pins2 {

					mux {
						groups = "pwm_i_h";
						function = "pwm_i";
					};
				};

				pwm_j_pins {

					mux {
						groups = "pwm_j";
						function = "pwm_j";
					};
				};

				pwm_a_hiz_pins {

					mux {
						groups = "pwm_a_hiz";
						function = "pwm_a_hiz";
					};
				};

				pwm_b_hiz_pins {

					mux {
						groups = "pwm_b_hiz";
						function = "pwm_b_hiz";
					};
				};

				pwm_c_hiz_pins {

					mux {
						groups = "pwm_c_hiz";
						function = "pwm_b_hiz";
					};
				};

				pwm_g_hiz_pins {

					mux {
						groups = "pwm_g_hiz";
						function = "pwm_g_hiz";
					};
				};

				remote_pin {
					phandle = <0x47>;

					mux {
						groups = "remote_in";
						function = "remote_in";
						bias-disable;
					};
				};

				spicc0_pins_x {
					phandle = <0x1a>;

					mux {
						groups = "spi_a_mosi_x", "spi_a_miso_x", "spi_a_clk_x";
						function = "spi_a";
						drive-strength = <0x2>;
					};
				};

				spicc0_pins_h {

					mux {
						groups = "spi_a_mosi_h", "spi_a_miso_h", "spi_a_clk_h";
						function = "spi_a";
						drive-strength = <0x2>;
					};
				};

				spicc0_pins_z {

					mux {
						groups = "spi_a_mosi_z", "spi_a_miso_z", "spi_a_clk_z";
						function = "spi_a";
						drive-strength = <0x2>;
					};
				};

				spifc_pins {
					phandle = <0x1c>;

					mux {
						groups = "spif_hold", "spif_mo", "spif_mi", "spif_clk", "spif_wp", "spif_cs";
						function = "spif";
						drive-strength-microamp = <0xbb8>;
					};
				};

				irblaster_pin {

					mux {
						groups = "remote_out";
						function = "remote_out";
					};
				};

				spdifin {

					mux {
						groups = "spdif_in";
						function = "spdif_in";
					};
				};

				tdm_a {
					phandle = <0x27>;

					mux {
						groups = "tdm_sclk0", "tdm_fs0", "tdm_d0", "tdm_d1";
						function = "tdm";
					};
				};

				pdmin {
					phandle = <0x2d>;

					mux {
						groups = "pdm_dclk_d", "pdm_din0_d";
						function = "pdm";
					};
				};

				spdifout {
					phandle = <0x2b>;

					mux {
						groups = "spdif_out_h";
						function = "spdif_out";
					};
				};

				spdifout_a_mute {
					phandle = <0x2c>;

					mux {
						groups = "GPIOH_4";
						function = "gpio_periphs";
						output-low;
					};
				};

				dvb_s_ts0_pins {
					phandle = <0x83>;

					tsin_a {
						groups = "tsin_a_sop", "tsin_a_valid", "tsin_a_clk", "tsin_a_din0";
						function = "tsin_a";
					};
				};
			};

			interrupt-controller@4080 {
				compatible = "amlogic,meson-s4-gpio-intc", "amlogic,meson-gpio-intc";
				reg = <0x0 0x4080 0x0 0x20>;
				interrupt-controller;
				#interrupt-cells = <0x2>;
				amlogic,channel-interrupts = <0xa 0xb 0xc 0xd 0xe 0xf 0x10 0x11 0x12 0x13 0x14 0x15>;
			};

			spi@50000 {
				compatible = "amlogic,meson-g12-spicc";
				reg = <0x0 0x50000 0x0 0x44>;
				interrupts = <0x0 0xb7 0x4>;
				clocks = <0xb 0x122 0xb 0xe0>;
				clock-names = "core", "async";
				#address-cells = <0x1>;
				#size-cells = <0x0>;
				status = "disabled";
				pinctrl-names = "default";
				pinctrl-0 = <0x1a>;
				cs-gpios = <0x1b 0x3a 0x0>;
			};

			spi@56000 {
				compatible = "amlogic,meson-spifc";
				status = "disabled";
				reg = <0x0 0x56000 0x0 0x80>;
				clock-names = "default";
				clocks = <0xb 0x114>;
				pinctrl-names = "default";
				pinctrl-0 = <0x1c>;
				#address-cells = <0x1>;
				#size-cells = <0x0>;

				spi-nor@0 {
					compatible = "jedec,spi-nor";
					status = "disabled";
					reg = <0x0>;
					spi-max-frequency = <0xf42400>;
				};
			};

			pwm@58000 {
				compatible = "amlogic,meson-v2-pwm";
				reg = <0x0 0x58000 0x0 0x24>;
				#pwm-cells = <0x3>;
				clocks = <0xb 0xe6 0xb 0xe9>;
				clock-names = "clkin0", "clkin1";
				status = "disabled";
			};

			pwm@5a000 {
				compatible = "amlogic,meson-v2-pwm";
				reg = <0x0 0x5a000 0x0 0x24>;
				#pwm-cells = <0x3>;
				clocks = <0xb 0xec 0xb 0xef>;
				clock-names = "clkin0", "clkin1";
				status = "disabled";
			};

			pwm@5c000 {
				compatible = "amlogic,meson-v2-pwm";
				reg = <0x0 0x5c000 0x0 0x24>;
				#pwm-cells = <0x3>;
				clocks = <0xb 0xf2 0xb 0xf5>;
				clock-names = "clkin0", "clkin1";
				status = "okay";
				pinctrl-0 = <0x1d>;
				pinctrl-names = "default";
				phandle = <0x50>;
			};

			pwm@5e000 {
				compatible = "amlogic,meson-v2-pwm";
				reg = <0x0 0x5e000 0x0 0x24>;
				#pwm-cells = <0x3>;
				clocks = <0xb 0xf8 0xb 0xfb>;
				clock-names = "clkin0", "clkin1";
				status = "disabled";
			};

			pwm@60000 {
				compatible = "amlogic,meson-v2-pwm";
				reg = <0x0 0x60000 0x0 0x24>;
				#pwm-cells = <0x3>;
				clocks = <0xb 0xfe 0xb 0x101>;
				clock-names = "clkin0", "clkin1";
				status = "okay";
				phandle = <0x17>;
			};

			i2c@66000 {
				compatible = "amlogic,meson-i2c";
				reg = <0x0 0x66000 0x0 0x48>;
				interrupts = <0x0 0xa0 0x1>;
				#address-cells = <0x1>;
				#size-cells = <0x0>;
				clocks = <0xb 0x127>;
				status = "disabled";
			};

			i2c@68000 {
				compatible = "amlogic,meson-i2c";
				reg = <0x0 0x68000 0x0 0x48>;
				interrupts = <0x0 0xa1 0x1>;
				#address-cells = <0x1>;
				#size-cells = <0x0>;
				clocks = <0xb 0x128>;
				status = "okay";
				pinctrl-names = "default";
				pinctrl-0 = <0x1e>;
				clock-frequency = <0x493e0>;

				tlc59116@60 {
					compatible = "amlogic,tlc59116_led";
					reg = <0x60>;
					status = "okay";

					led0 {
						default_colors = <0x0 0x0 0x0>;
						r_io_number = <0x0>;
						g_io_number = <0xa>;
						b_io_number = <0x5>;
					};

					led1 {
						default_colors = <0x0 0x0 0x0>;
						r_io_number = <0x1>;
						g_io_number = <0xb>;
						b_io_number = <0x6>;
					};

					led2 {
						default_colors = <0x0 0x0 0x0>;
						r_io_number = <0x2>;
						g_io_number = <0xc>;
						b_io_number = <0x7>;
					};

					led3 {
						default_colors = <0x0 0x0 0x0>;
						r_io_number = <0x3>;
						g_io_number = <0xd>;
						b_io_number = <0x8>;
					};
				};
			};

			i2c@6a000 {
				compatible = "amlogic,meson-i2c";
				reg = <0x0 0x6a000 0x0 0x48>;
				interrupts = <0x0 0xa2 0x1>;
				#address-cells = <0x1>;
				#size-cells = <0x0>;
				clocks = <0xb 0x129>;
				status = "disabled";
			};

			i2c@6c000 {
				compatible = "amlogic,meson-i2c";
				reg = <0x0 0x6c000 0x0 0x48>;
				interrupts = <0x0 0xa3 0x1>;
				#address-cells = <0x1>;
				#size-cells = <0x0>;
				clocks = <0xb 0x12a>;
				status = "okay";
				pinctrl-names = "default";
				pinctrl-0 = <0x1f>;
				clock-frequency = <0x493e0>;
				phandle = <0x82>;
			};

			i2c@6e000 {
				compatible = "amlogic,meson-i2c";
				reg = <0x0 0x6e000 0x0 0x48>;
				interrupts = <0x0 0xa4 0x1>;
				#address-cells = <0x1>;
				#size-cells = <0x0>;
				clocks = <0xb 0x12b>;
				status = "okay";
				pinctrl-names = "default";
				pinctrl-0 = <0x20>;
				clock-frequency = <0x493e0>;
				phandle = <0x81>;
			};

			serial@7a000 {
				compatible = "amlogic,meson-uart";
				reg = <0x0 0x7a000 0x0 0x18>;
				interrupts = <0x0 0xa9 0x1>;
				status = "okay";
				clocks = <0x18>;
				clock-names = "clk_uart";
				xtal_tick_en = <0x2>;
				fifosize = <0x40>;
				support-sysrq = <0x0>;
			};

			mdio-multiplexer@28000 {
				compatible = "amlogic,g12a-mdio-mux";
				reg = <0x0 0x28000 0x0 0xa4>;
				clocks = <0xb 0x10a 0x18 0xb 0x32>;
				clock-names = "pclk", "clkin0", "clkin1";
				mdio-parent-bus = <0x21>;
				#address-cells = <0x1>;
				#size-cells = <0x0>;
				enet_type = <0x5>;
				tx_amp_src = <0xfe010330>;

				mdio@0 {
					reg = <0x0>;
					#address-cells = <0x1>;
					#size-cells = <0x0>;
				};

				mdio@1 {
					reg = <0x1>;
					#address-cells = <0x1>;
					#size-cells = <0x0>;

					ethernet_phy@8 {
						compatible = "ethernet-phy-id0180.3301", "ethernet-phy-ieee802.3-c22";
						interrupts = <0x0 0x4b 0x4>;
						reg = <0x8>;
						max-speed = <0x64>;
						phandle = <0x3b>;
					};
				};
			};

			reset-controller@2000 {
				compatible = "amlogic,meson-sc2-reset";
				reg = <0x0 0x2000 0x0 0x98>;
				#reset-cells = <0x1>;
				phandle = <0x24>;
			};

			cpu_version {
				compatible = "amlogic,meson-gx-ao-secure", "syscon";
				reg = <0x0 0x10220 0x0 0x4>;
			};
		};

		usb2phy@fe03a000 {
			compatible = "amlogic,amlogic-new-usb2-v2";
			status = "okay";
			#phy-cells = <0x0>;
			reg = <0x0 0xfe03a000 0x0 0x80 0x0 0xfe002000 0x0 0x100 0x0 0xfe03c000 0x0 0x2000 0x0 0xfe03e000 0x0 0x2000>;
			pll-setting-1 = <0x9400414>;
			pll-setting-2 = <0x927e0000>;
			pll-setting-3 = <0xac5f69e5>;
			pll-setting-4 = <0xbe18>;
			pll-setting-5 = <0x7>;
			pll-setting-6 = <0x78000>;
			pll-setting-7 = <0xe0004>;
			pll-setting-8 = <0xe000c>;
			version = <0x3>;
			phy20-reset-level-bit = <0x8>;
			phy21-reset-level-bit = <0x9>;
			usb-reset-bit = <0x4>;
			reset-level = <0x40>;
			portnum = <0x2>;
			phandle = <0x22>;
		};

		usb3phy@fe03a080 {
			compatible = "amlogic,amlogic-new-usb3-v2";
			status = "okay";
			#phy-cells = <0x0>;
			reg = <0x0 0xfe03a080 0x0 0x20 0x0 0xfe002000 0x0 0x100>;
			phy-reg = <0xfe02a000>;
			phy-reg-size = <0x2000>;
			usb2-phy-reg = <0xfe03a000>;
			usb2-phy-reg-size = <0x80>;
			clocks = <0xb 0x2d>;
			clock-names = "pcie_refpll";
			interrupts = <0x0 0x81 0x4>;
			portnum = <0x0>;
			otg = <0x0>;
			phandle = <0x23>;
		};

		crg@fde00000 {
			compatible = "amlogic, crg";
			status = "okay";
			reg = <0x0 0xfde00000 0x0 0x100000>;
			interrupts = <0x0 0x82 0x4>;
			usb-phy = <0x22 0x23>;
			cpu-type = "gxl";
			clock-src = "usb3.0";
			clocks = <0xb 0x125>;
			clock-names = "crg_general";
		};

		dummy {
			#sound-dai-cells = <0x0>;
			compatible = "amlogic, aml_dummy_codec";
			status = "okay";
			phandle = <0x99>;
		};

		t9015 {
			#sound-dai-cells = <0x0>;
			compatible = "amlogic, s4_codec_T9015";
			reg = <0x0 0xfe01a000 0x0 0x2000>;
			tocodec_inout = <0x2>;
			tdmout_index = <0x2>;
			ch0_sel = <0x0>;
			ch1_sel = <0x1>;
			reset-names = "acodec";
			resets = <0x24 0x58>;
			status = "okay";
			phandle = <0x9c>;
		};

		audiobus@0xFE330000 {
			compatible = "amlogic, audio-controller", "simple-bus";
			reg = <0x0 0xfe330000 0x0 0x3000>;
			#address-cells = <0x2>;
			#size-cells = <0x2>;
			ranges = <0x0 0x0 0x0 0xfe330000 0x0 0x3000>;
			power-domains = <0x25 0x7>;

			audio_clocks {
				compatible = "amlogic, sm1-audio-clocks";
				#clock-cells = <0x1>;
				reg = <0x0 0x0 0x0 0xb0>;
				phandle = <0x26>;
			};

			ddr_manager {
				compatible = "amlogic, t5-audio-ddr-manager";
				interrupts = <0x0 0x20 0x1 0x0 0x21 0x1 0x0 0x22 0x1 0x0 0x2d 0x1 0x0 0x24 0x1 0x0 0x25 0x1 0x0 0x26 0x1 0x0 0x2e 0x1>;
				interrupt-names = "toddr_a", "toddr_b", "toddr_c", "toddr_d", "frddr_a", "frddr_b", "frddr_c", "frddr_d";
			};

			pinctrl {
				compatible = "amlogic, audio-pinctrl";

				tdm_d0_pin {
					phandle = <0x28>;

					mux {
						groups = "tdm_d0";
						function = "tdmouta_lane0";
					};
				};

				tdm_d1_pin {
					phandle = <0x29>;

					mux {
						groups = "tdm_d1";
						function = "tdmina_lane1";
					};
				};

				tdm_clk_pin {
					phandle = <0x2a>;

					mux {
						groups = "tdm_sclk0", "tdm_lrclk0";
						function = "tdm_clk_outa";
					};
				};
			};

			tdm@0 {
				compatible = "amlogic, t5-snd-tdma";
				#sound-dai-cells = <0x0>;
				dai-tdm-lane-slot-mask-in = <0x0 0x1>;
				dai-tdm-lane-slot-mask-out = <0x1 0x0>;
				dai-tdm-clk-sel = <0x0>;
				clocks = <0x26 0x24 0xb 0x35>;
				clock-names = "mclk", "clk_srcpll";
				pinctrl-names = "tdm_pins";
				pinctrl-0 = <0x27 0x28 0x29 0x2a>;
				status = "okay";
				phandle = <0x98>;
			};

			tdm@1 {
				compatible = "amlogic, t5-snd-tdmb";
				#sound-dai-cells = <0x0>;
				dai-tdm-lane-slot-mask-in = <0x0 0x1 0x0 0x0>;
				dai-tdm-lane-slot-mask-out = <0x1 0x1 0x1 0x1>;
				dai-tdm-clk-sel = <0x1>;
				clocks = <0x26 0x25 0xb 0x37>;
				clock-names = "mclk", "clk_srcpll";
				pinctrl-names = "tdm_pins";
				pinctrl-0;
				i2s2hdmi = <0x1>;
				status = "okay";
				phandle = <0x9a>;
			};

			tdm@2 {
				compatible = "amlogic, t5-snd-tdmc";
				#sound-dai-cells = <0x0>;
				dai-tdm-lane-slot-mask-in = <0x1>;
				dai-tdm-lane-slot-mask-out = <0x1>;
				dai-tdm-clk-sel = <0x2>;
				clocks = <0x26 0x26 0x26 0x3a 0xb 0x39>;
				clock-names = "mclk", "mclk_pad", "clk_srcpll";
				samesource_sel = <0x3>;
				start_clk_enable = <0x1>;
				clk_tuning_enable = <0x1>;
				status = "okay";
				phandle = <0x9b>;
			};

			spdif@0 {
				compatible = "amlogic, tm2-revb-snd-spdif-a";
				#sound-dai-cells = <0x0>;
				clocks = <0xb 0x35 0xb 0x9 0x26 0x10 0x26 0x11 0x26 0x2a 0x26 0x2b>;
				clock-names = "sysclk", "fixed_clk", "gate_spdifin", "gate_spdifout", "clk_spdifin", "clk_spdifout";
				interrupts = <0x0 0x23 0x1>;
				interrupt-names = "irq_spdifin";
				pinctrl-names = "spdif_pins", "spdif_pins_mute";
				pinctrl-0 = <0x2b>;
				pinctrl-1 = <0x2c>;
				clk_tuning_enable = <0x1>;
				status = "okay";
				phandle = <0x9e>;
			};

			spdif@1 {
				compatible = "amlogic, tm2-revb-snd-spdif-b";
				#sound-dai-cells = <0x0>;
				clocks = <0xb 0x37 0x26 0x15 0x26 0x31>;
				clock-names = "sysclk", "gate_spdifout", "clk_spdifout";
				status = "okay";
				phandle = <0x9f>;
			};

			pdm {
				compatible = "amlogic, sm1-snd-pdm";
				#sound-dai-cells = <0x0>;
				clocks = <0x26 0x1 0xb 0x7 0xb 0x3b 0x26 0x2f 0x26 0x30>;
				clock-names = "gate", "sysclk_srcpll", "dclk_srcpll", "pdm_dclk", "pdm_sysclk";
				pinctrl-names = "pdm_pins";
				pinctrl-0 = <0x2d>;
				filter_mode = <0x1>;
				status = "okay";
				phandle = <0x9d>;
			};

			resample@0 {
				compatible = "amlogic, t5-resample-a";
				clocks = <0xb 0x3b 0x26 0x29 0x26 0x2c>;
				clock-names = "resample_pll", "resample_src", "resample_clk";
				resample_module = <0x4>;
				status = "disabled";
			};

			resample@1 {
				compatible = "amlogic, t5-resample-b";
				clocks = <0xb 0x3b 0x26 0x29 0x26 0x32>;
				clock-names = "resample_pll", "resample_src", "resample_clk";
				capture_sample_rate = <0x3e80>;
				status = "disabled";
			};

			vad {
				compatible = "amlogic, snd-vad";
				#sound-dai-cells = <0x0>;
				clocks = <0x26 0x1b 0xb 0xb 0x26 0x35>;
				clock-names = "gate", "pll", "clk";
				interrupts = <0x0 0x27 0x1 0x0 0x2c 0x1>;
				interrupt-names = "irq_wakeup", "irq_frame_sync";
				src = <0x4>;
				level = <0x1>;
				status = "okay";
			};

			loopback@0 {
				compatible = "amlogic, t5-loopbacka";
				#sound-dai-cells = <0x0>;
				clocks = <0x26 0x1 0xb 0x7 0xb 0x3b 0x26 0x2f 0x26 0x30 0xb 0x35 0x26 0x24>;
				clock-names = "pdm_gate", "pdm_sysclk_srcpll", "pdm_dclk_srcpll", "pdm_dclk", "pdm_sysclk", "tdminlb_mpll", "tdminlb_mclk";
				datain_src = <0x4>;
				datain_chnum = <0x2>;
				datain_chmask = <0x3>;
				datain-lane-mask-in = <0x1 0x0 0x0 0x0>;
				mclk-fs = <0x100>;
				datalb_src = <0x1>;
				datalb_chnum = <0x2>;
				datalb_chmask = <0x3>;
				datalb-lane-mask-in = <0x1 0x0 0x0 0x0>;
				status = "okay";
				phandle = <0xa0>;
			};

			loopback@1 {
				compatible = "amlogic, t5-loopbackb";
				#sound-dai-cells = <0x0>;
				clocks = <0x26 0x1 0xb 0x7 0xb 0x3b 0x26 0x2f 0x26 0x30 0xb 0x35 0x26 0x24>;
				clock-names = "pdm_gate", "pdm_sysclk_srcpll", "pdm_dclk_srcpll", "pdm_dclk", "pdm_sysclk", "tdminlb_mpll", "tdminlb_mclk";
				mclk-fs = <0x100>;
				datain_src = <0x4>;
				datain_chnum = <0x4>;
				datain_chmask = <0xf>;
				datain-lane-mask-in = <0x1 0x0 0x1 0x0>;
				datalb_src = <0x1>;
				datalb_chnum = <0x2>;
				datalb_chmask = <0x3>;
				datalb-lane-mask-in = <0x1 0x0 0x0 0x0>;
				status = "disabled";
			};

			effect {
				compatible = "amlogic, snd-effect-v3";
				#sound-dai-cells = <0x0>;
				clocks = <0x26 0x16 0xb 0xb 0x26 0x34>;
				clock-names = "gate", "srcpll", "eqdrc";
				eqdrc_module = <0x2>;
				lane_mask = <0x1>;
				channel_mask = <0x3>;
				status = "okay";
			};
		};

		aml_snd_iomap {
			compatible = "amlogic, snd-iomap";
			status = "okay";
			#address-cells = <0x2>;
			#size-cells = <0x2>;
			ranges;

			pdm_bus {
				reg = <0x0 0xfe331000 0x0 0x400>;
			};

			audiobus_base {
				reg = <0x0 0xfe330000 0x0 0x1000>;
			};

			audiolocker_base {
				reg = <0x0 0xfe331400 0x0 0x400>;
			};

			eqdrc_base {
				reg = <0x0 0xfe332000 0x0 0x1000>;
			};

			vad_base {
				reg = <0x0 0xfe331800 0x0 0x400>;
			};

			resampleA_base {
				reg = <0x0 0xfe331c00 0x0 0x104>;
			};

			resampleB_base {
				reg = <0x0 0xfe334000 0x0 0x104>;
			};
		};

		dwc2_a@fdd00000 {
			compatible = "amlogic,dwc2";
			status = "okay";
			device_name = "dwc2_a";
			reg = <0x0 0xfdd00000 0x0 0x100000>;
			interrupts = <0x0 0x83 0x4>;
			pl-periph-id = <0x0>;
			clock-src = "usb0";
			port-id = <0x0>;
			port-type = <0x2>;
			port-speed = <0x0>;
			port-config = <0x0>;
			port-dma = <0x0>;
			port-id-mode = <0x0>;
			usb-fifo = <0x2d8>;
			cpu-type = "v2";
			phy-reg = <0xfe03a000>;
			phy-reg-size = <0xa0>;
			phy-interface = <0x2>;
			clocks = <0xb 0x125 0xb 0x12f>;
			clock-names = "usb_general", "usb1";
			controller-type = <0x1>;
		};

		dolby_fw {
			compatible = "amlogic, dolby_fw";
			mem_size = <0x100000>;
			status = "okay";
		};

		pcie@f5000000 {
			compatible = "amlogic, amlogic-pcie-v2", "snps,dw-pcie";
			reg = <0x0 0xf5000000 0x0 0x400000 0x0 0xfe02c000 0x0 0x2000 0x0 0xf5400000 0x0 0x200000 0x0 0xfe02a000 0x0 0x2000 0x0 0xfe002044 0x0 0x10>;
			reg-names = "elbi", "cfg", "config", "phy", "reset";
			interrupts = <0x0 0x8d 0x1>;
			#interrupt-cells = <0x1>;
			bus-range = <0x0 0xff>;
			#address-cells = <0x3>;
			#size-cells = <0x2>;
			interrupt-map-mask = <0x0 0x0 0x0 0x0>;
			interrupt-map = <0x0 0x0 0x0 0x0 0x1 0x0 0x8f 0x1>;
			device_type = "pci";
			ranges = <0x81000000 0x0 0x0 0x0 0xf5600000 0x0 0x100000 0x82000000 0x0 0xf5700000 0x0 0xf5700000 0x0 0x1900000>;
			num-lanes = <0x1>;
			pcie-num = <0x1>;
			clocks = <0xb 0x2d 0xb 0x124 0xb 0x126>;
			clock-names = "pcie_refpll", "pcie", "pcie_phy";
			gpio-type = <0x2>;
			pcie-apb-rst-bit = <0xe>;
			pcie-phy-rst-bit = <0xd>;
			pcie-ctrl-a-rst-bit = <0xc>;
			pwr-ctl = <0x0>;
			pcie-ctrl-sleep-shift = <0xf>;
			pcie-hhi-mem-pd-shift = <0x1a>;
			pcie-hhi-mem-pd-mask = <0xf>;
			pcie-ctrl-iso-shift = <0xf>;
			status = "disable";
			reset-gpio = <0x1b 0x37 0x0>;
		};

		mmc@fe08c000 {
			compatible = "amlogic,meson-axg-mmc";
			reg = <0x0 0xfe08c000 0x0 0x800 0x0 0xfe000168 0x0 0x4 0x0 0xfe004000 0x0 0x4>;
			interrupts = <0x0 0xb2 0x1>;
			status = "okay";
			clocks = <0xb 0x111 0xb 0xd5 0xb 0xd7 0x18 0xb 0x29 0xb 0x29>;
			clock-names = "core", "mux0", "mux1", "clkin0", "clkin1", "clkin2";
			card_type = <0x1>;
			ignore_desc_busy;
			mmc_debug_flag;
			src_clk_rate = <0x44aa2000>;
			pinctrl-0 = <0x2e 0x2f>;
			pinctrl-1 = <0x30>;
			pinctrl-names = "default", "clk-gate";
			bus-width = <0x8>;
			cap-mmc-highspeed;
			mmc-ddr-1_8v;
			mmc-hs200-1_8v;
			max-frequency = <0xbebc200>;
			non-removable;
			disable-wp;
		};

		sd@fe08a000 {
			compatible = "amlogic,meson-axg-mmc";
			reg = <0x0 0xfe08a000 0x0 0x800 0x0 0xfe00016c 0x0 0x4 0x0 0xfe004024 0x0 0x4>;
			interrupts = <0x0 0xb1 0x1>;
			status = "okay";
			clocks = <0xb 0x110 0xb 0xdb 0xb 0xdd 0x18 0xb 0x5>;
			clock-names = "core", "mux0", "mux1", "clkin0", "clkin1";
			card_type = <0x5>;
			mmc_debug_flag;
			pinctrl-0 = <0x31>;
			pinctrl-1 = <0x32>;
			pinctrl-2 = <0x33>;
			pinctrl-3 = <0x34 0x31 0x35>;
			pinctrl-4 = <0x34 0x33 0x35>;
			pinctrl-5 = <0x31 0x36>;
			pinctrl-6 = <0x34 0x35>;
			pinctrl-7 = <0x31 0x36>;
			pinctrl-8 = <0x34 0x35>;
			pinctrl-names = "sd_default", "clk-gate", "sd_1bit_pins", "sd_clk_cmd_uart_pins", "sd_1bit_uart_pins", "sd_to_ao_uart_pins", "ao_to_sd_uart_pins", "sd_to_ao_jtag_pins", "ao_to_sd_jtag_pins";
			bus-width = <0x4>;
			cap-sd-highspeed;
			max-frequency = <0xbebc200>;
			disable-wp;
			cd-gpios = <0x1b 0x14 0x0>;
			dat1-gpios = <0x1b 0xf 0x0>;
		};

		sdio@fe088000 {
			compatible = "amlogic,meson-axg-mmc";
			reg = <0x0 0xfe088000 0x0 0x800 0x0 0xfe00016c 0x0 0x4 0x0 0xfe00400c 0x0 0x4>;
			interrupts = <0x0 0xb0 0x4>;
			status = "okay";
			clocks = <0xb 0x10f 0xb 0xd8 0xb 0xda 0x18 0xb 0x5>;
			clock-names = "core", "mux0", "mux1", "clkin0", "clkin1";
			card_type = <0x3>;
			mmc_debug_flag;
			cap-sdio-irq;
			keep-power-in-suspend;
			use_intf3_tuning;
			pinctrl-0 = <0x37>;
			pinctrl-1 = <0x38>;
			pinctrl-names = "default", "clk-gate";
			#address-cells = <0x1>;
			#size-cells = <0x0>;
			bus-width = <0x4>;
			cap-sd-highspeed;
			sd-uhs-sdr50;
			sd-uhs-sdr104;
			max-frequency = <0xbebc200>;
			non-removable;
			disable-wp;

			wifi@1 {
				reg = <0x1>;
				compatible = "brcm,bcm4329-fmac";
			};
		};

		nfc@fe08c800 {
			compatible = "amlogic,meson-nfc-single-ecc-bl2ex";
			status = "disabled";
			reg = <0x0 0xfe08c800 0x0 0x200>;
			interrupts = <0x0 0xaf 0x1>;
			clocks = <0xb 0x111 0xb 0x5>;
			clock-names = "gate", "fdiv2pll";
			nand_clk_ctrl = <0xfe08c000>;
			#address-cells = <0x1>;
			#size-cells = <0x0>;
			pinctrl-names = "nand_norb_mod", "nand_cs_only";
			pinctrl-0 = <0x39>;
			pinctrl-1 = <0x3a>;
			bl_mode = <0x1>;
			fip_copies = <0x4>;
			fip_size = <0x200000>;
			ship_bad_block = <0x1>;
			disa_irq_flag = <0x1>;

			nand@bootloader {
				reg = <0x0>;
				#address-cells = <0x1>;
				#size-cells = <0x1>;
				nand-ecc-maximize;

				partition@0 {
					label = "bootloader";
					reg = <0x0 0x0>;
				};
			};

			nand@normal {
				reg = <0x0>;
				#address-cells = <0x1>;
				#size-cells = <0x1>;
				nand-ecc-maximize;

				partition@0 {
					label = "bl2e";
					reg = <0x0 0x0>;
				};

				partition@1 {
					label = "bl2x";
					reg = <0x0 0x0>;
				};

				partition@2 {
					label = "ddrfip";
					reg = <0x0 0x0>;
				};

				partition@3 {
					label = "tpl";
					reg = <0x0 0x0>;
				};

				partition@4 {
					label = "logo";
					reg = <0x0 0x200000>;
				};

				partition@5 {
					label = "recovery";
					reg = <0x0 0x1000000>;
				};

				partition@6 {
					label = "boot";
					reg = <0x0 0xf00000>;
				};

				partition@7 {
					label = "system";
					reg = <0x0 0x11800000>;
				};

				partition@8 {
					label = "data";
					reg = <0x0 0xffffffff>;
				};
			};
		};

		ethernet@fdc00000 {
			compatible = "amlogic,meson-axg-dwmac", "snps,dwmac-3.70a", "snps,dwmac";
			reg = <0x0 0xfdc00000 0x0 0x10000 0x0 0xfe024000 0x0 0x8>;
			interrupts = <0x0 0x4a 0x4>;
			interrupt-names = "macirq";
			power-domains = <0x25 0x5>;
			clocks = <0xb 0x118 0xb 0x5 0xb 0x39>;
			clock-names = "stmmaceth", "clkin0", "clkin1";
			rx-fifo-depth = <0x1000>;
			tx-fifo-depth = <0x800>;
			status = "okay";
			phy-handle = <0x3b>;
			phy-mode = "rmii";

			mdio {
				#address-cells = <0x1>;
				#size-cells = <0x0>;
				compatible = "snps,dwmac-mdio";
				phandle = <0x21>;
			};
		};

		serial@fe078000 {
			compatible = "amlogic,meson-uart";
			reg = <0x0 0xfe078000 0x0 0x18>;
			interrupts = <0x0 0xa8 0x1>;
			status = "okay";
			clocks = <0x18 0xb 0x119>;
			clock-names = "clk_uart", "clk_gate";
			xtal_tick_en = <0x3>;
			fifosize = <0x40>;
			pinctrl-names = "default";
			pinctrl-0 = <0x3c>;
			uart-has-rtscts;
		};

		serial@fe07c000 {
			compatible = "amlogic,meson-uart";
			reg = <0x0 0xfe07c000 0x0 0x18>;
			interrupts = <0x0 0xaa 0x1>;
			status = "disabled";
			clocks = <0x18 0xb 0x11b>;
			clock-names = "clk_uart", "clk_gate";
			fifosize = <0x40>;
			pinctrl-names = "default";
			pinctrl-0 = <0x3d>;
		};

		serial@fe07e000 {
			compatible = "amlogic,meson-uart";
			status = "disabled";
			reg = <0x0 0xfe07e000 0x0 0x18>;
			interrupts = <0x0 0xab 0x1>;
			clocks = <0x18 0xb 0x11c>;
			clock-names = "clk_uart", "clk_gate";
			fifosize = <0x40>;
			pinctrl-names = "default";
			pinctrl-0 = <0x3e>;
		};

		serial@fe080000 {
			compatible = "amlogic,meson-uart";
			status = "disabled";
			reg = <0x0 0xfe080000 0x0 0x18>;
			interrupts = <0x0 0xac 0x1>;
			clocks = <0x18 0xb 0x11d>;
			clock-names = "clk_uart", "clk_gate";
			fifosize = <0x40>;
			pinctrl-names = "default";
			pinctrl-0 = <0x3f>;
		};
	};

	mesonstream {
		compatible = "amlogic, codec, streambuf";
		dev_name = "mesonstream";
		status = "okay";
		clocks = <0xb 0x109 0xb 0x98 0xb 0x9f 0xb 0xad 0xb 0xa6>;
		clock-names = "vdec", "clk_vdec_mux", "clk_hcodec_mux", "clk_hevcf_mux", "clk_hevcb_mux";
	};

	vdec {
		compatible = "amlogic, vdec-pm-pd";
		dev_name = "vdec.0";
		status = "okay";
		interrupts = <0x0 0x3 0x1 0x0 0x17 0x1 0x0 0x20 0x1 0x0 0x5b 0x1 0x0 0x5c 0x1 0x0 0x5d 0x1 0x0 0x48 0x1>;
		interrupt-names = "vsync", "demux", "parser", "mailbox_0", "mailbox_1", "mailbox_2", "parser_b";
		power-domains = <0x25 0x1 0x25 0x0>;
		power-domain-names = "pwrc-vdec", "pwrc-hevc";
	};

	cpu_ver_name {
		compatible = "amlogic, cpu-major-id-s4";
	};

	vcodec_dec {
		compatible = "amlogic, vcodec-dec";
		dev_name = "aml-vcodec-dec";
		status = "okay";
	};

	ddr_bandwidth {
		compatible = "amlogic,ddr-bandwidth-s4";
		status = "okay";
		reg = <0x0 0xfe036000 0x0 0x400 0x0 0xfe036c00 0x0 0x100>;
		interrupts = <0x0 0x4e 0x1>;
		interrupt-names = "ddr_bandwidth";
	};

	dmc_monitor {
		compatible = "amlogic,dmc_monitor-s4";
		status = "okay";
		reg = <0x0 0xfe036000 0x0 0x400>;
		reg_base = <0xfe037000>;
		interrupts = <0x0 0x3e 0x1>;
	};

	amhdmitx {
		compatible = "amlogic, amhdmitx-sc2";
		dev_name = "amhdmitx";
		status = "okay";
		power-domains = <0x25 0x2>;
		vend-data = <0x40>;
		pinctrl-names = "default";
		pinctrl-0 = <0x41 0x42>;
		clock-names = "venci_top_gate", "venci_0_gate", "venci_1_gate", "hdmi_vapb_clk", "hdmi_vpu_clk";
		interrupts = <0x0 0xcc 0x1 0x0 0xc5 0x1>;
		interrupt-names = "hdmitx_hpd", "viu1_vsync";
		ic_type = <0xf>;
		hdmi_rext = <0x514>;
		reg = <0x0 0x0 0x0 0x0 0x0 0xff000000 0x0 0x40000 0x0 0x0 0x0 0x0 0x0 0xfe308000 0x0 0x8000 0x0 0xfe300000 0x0 0x8000 0x0 0xfe032000 0x0 0x100 0x0 0xfe008000 0x0 0x400 0x0 0xfe00c000 0x0 0x800 0x0 0xfe002000 0x0 0x400 0x0 0xfe010000 0x0 0x100 0x0 0xfe000000 0x0 0x2000>;
		reg-names = "cbus", "vpu", "hiu", "hdmitxdwc", "hdmitxtop", "esm", "anactrl", "pwrctrl", "resetctrl", "sysctrl", "clkctrl";

		vend_data {
			vendor_name = "Amlogic";
			product_desc = "MBox Meson Ref";
			vendor_id = <0x0>;
			phandle = <0x40>;
		};
	};

	aocec {
		compatible = "amlogic, aocec-s4";
		dev_name = "aocec";
		status = "okay";
		vendor_name = "Amlogic";
		vendor_id = <0xffffff>;
		product_desc = "S4";
		cec_osd_string = "AML_MBOX";
		cec_version = <0x5>;
		port_num = <0x1>;
		output = <0x1>;
		cec_sel = <0x1>;
		ee_cec;
		arc_port_mask = <0x1>;
		interrupts = <0x0 0xb4 0x1 0x0 0xb3 0x1>;
		interrupt-names = "hdmi_aocecb", "hdmi_aocec";
		pinctrl-names = "default", "hdmitx_aocecb", "cec_pin_sleep";
		pinctrl-0 = <0x43>;
		pinctrl-1 = <0x44>;
		pinctrl-2 = <0x44>;
		clocks = <0xb 0x4c 0xb 0x51>;
		clock-names = "ceca_clk", "cecb_clk";
		reg = <0x0 0xfe044000 0x0 0x2ff 0x0 0xfe010000 0x0 0xfff 0x0 0xfe000000 0x0 0xfff>;
		reg-names = "ao", "periphs", "clock";
	};

	aml_dma {
		compatible = "amlogic,aml_txlx_dma";
		reg = <0x0 0xfe440400 0x0 0x48>;
		interrupts = <0x0 0x18 0x1>;

		aml_aes {
			compatible = "amlogic,aes_g12a_dma";
			dev_name = "aml_aes_dma";
			status = "okay";
			iv_swap = [00];
		};

		aml_sha {
			compatible = "amlogic,sha_dma";
			dev_name = "aml_sha_dma";
			status = "okay";
		};

		aml_tdes {
			compatible = "amlogic,des_dma,tdes_dma";
			dev_name = "aml_tdes_dma";
			status = "okay";
		};
	};

	rng {
		compatible = "amlogic,meson-rng";
		status = "okay";
		#address-cells = <0x2>;
		#size-cells = <0x2>;
		reg = <0x0 0xfe440788 0x0 0xc>;
		quality = [03 e8];
		version = <0x2>;
	};

	canvas {
		compatible = "amlogic, meson, canvas";
		status = "okay";
		reg = <0x0 0xfe036048 0x0 0x2000>;
	};

	codec_io {
		compatible = "amlogic, meson-s4, codec-io";
		status = "okay";
		#address-cells = <0x2>;
		#size-cells = <0x2>;
		ranges;
		reg = <0x0 0xfe002000 0x0 0x2000 0x0 0xfe320000 0x0 0x10000 0x0 0x0 0x0 0x0 0x0 0x0 0x0 0x0 0x0 0xff000000 0x0 0x40000 0x0 0xfe036000 0x0 0x2000 0x0 0x0 0x0 0x0>;
		reg-names = "cbus", "dosbus", "hiubus", "aobus", "vcbus", "dmcbus", "efusebus";
	};

	amvenc_avc {
		compatible = "amlogic, amvenc_avc";
		dev_name = "amvenc_avc";
		status = "disabled";
		clocks = <0xb 0x9b>;
		clock-names = "cts_hcodec_aclk";
		interrupts = <0x0 0x5d 0x1>;
		interrupt-names = "mailbox_2";
		reset-names = "hcodec_rst";
		resets = <0x24 0xa3>;
	};

	jpegenc {
		compatible = "amlogic, jpegenc";
		dev_name = "jpegenc";
		status = "disabled";
		clocks = <0xb 0x9b>;
		clock-names = "cts_jpegenc_aclk";
		interrupts = <0x0 0x5d 0x1>;
		interrupt-names = "mailbox_2";
		reset-names = "jpegenc_rst";
		resets = <0x24 0xa3>;
	};

	hevc_enc {
		compatible = "cnm, HevcEnc";
		dev_name = "HevcEnc";
		status = "disabled";
		interrupts = <0x0 0x5e 0x1>;
		interrupt-names = "wave420l_irq";
		#address-cells = <0x2>;
		#size-cells = <0x2>;
		clocks = <0xb 0xb0 0xb 0xb3 0xb 0xb6>;
		clock-names = "cts_wave420_aclk", "cts_wave420_bclk", "cts_wave420_cclk";
		ranges;

		io_reg_base {
			reg = <0x0 0xfe310000 0x0 0x4000>;
		};
	};

	vpu {
		compatible = "amlogic, vpu-s4";
		status = "okay";
		reg = <0x0 0xfe000000 0x0 0x100 0x0 0xfe00c000 0x0 0x70 0x0 0xff000000 0x0 0xa000>;
		clocks = <0xb 0xd0 0xb 0x135 0xb 0xb9 0xb 0xbc 0xb 0xbd>;
		clock-names = "vapb_clk", "vpu_intr_gate", "vpu_clk0", "vpu_clk1", "vpu_clk";
		clk_level = <0x7>;
	};

	rdma {
		compatible = "amlogic, meson-sc2, rdma";
		status = "okay";
		interrupts = <0x0 0xd7 0x1>;
		interrupt-names = "rdma";
		reset-names = "rdma";
		resets = <0x24 0x1c>;
	};

	vclk_serve {
		compatible = "amlogic, vclk_serve";
		status = "okay";
		reg = <0x0 0xfe008000 0x0 0x300 0x0 0xfe000000 0x0 0x4a0>;
	};

	vdac {
		compatible = "amlogic, vdac-s4";
		status = "okay";
	};

	vout {
		compatible = "amlogic, vout";
		status = "okay";
		fr_policy = <0x2>;
	};

	dummy_venc {
		compatible = "amlogic, dummy_venc_s4";
		status = "okay";
	};

	adc {
		compatible = "amlogic, adc-s4";
		status = "okay";
		reg = <0x0 0xff654000 0x0 0x2000 0x0 0xfe008000 0x0 0x2000>;
	};

	ledlight {
		compatible = "amlogic, ledlight";
		dev_name = "ledlight";
		status = "okay";
		power_gpio_0 = <0x45>;

		gpio_b {
			led_name = "power_led";
			led_gpio = <0x1b 0x22 0x0>;
			led_active = <0x1>;
			led_type = [42 00];
			phandle = <0x45>;
		};
	};

	fd650_dev {
		compatible = "amlogic,fd650_dev";
		dev_name = "fd650_dev";
		status = "okay";
		brightness_level = <0x2>;
		is_rotation_display = <0x0>;
		fd650_gpio_clk_name = "GPIOD_7";
		fd650_gpio_clk = <0x1b 0x1f 0x0>;
		fd650_gpio_dat_name = "GPIOD_6";
		fd650_gpio_dat = <0x1b 0x1e 0x0>;
	};

	ir@8000 {
		compatible = "amlogic, meson-ir";
		reg = <0x0 0xfe084040 0x0 0x44 0x0 0xfe084000 0x0 0x20>;
		status = "okay";
		protocol = <0x1>;
		interrupts = <0x0 0x16 0x1>;
		map = <0x46>;
		max_frame_time = <0xc8>;
		pinctrl-0 = <0x47>;
		pinctrl-names = "default";
	};

	p_tsensor@fe020000 {
		compatible = "amlogic, r1p1-tsensor";
		status = "okay";
		reg = <0x0 0xfe020000 0x0 0x50>;
		tsensor_id = <0x1>;
		cal_type = <0x11>;
		cal_coeff = <0x144 0x1a8 0xc57 0x24c3>;
		rtemp = <0x1adb0>;
		interrupts = <0x0 0x1e 0x4>;
		clocks = <0xb 0x8a>;
		clock-names = "ts_comp";
		#thermal-sensor-cells = <0x1>;
		phandle = <0x48>;
	};

	meson-cooldev@0 {
		status = "okay";
		compatible = "amlogic, meson-cooldev";

		cooling_devices {

			cpucore_cool_cluster0 {
				cluster_id = <0x0>;
				node_name = "cpucore_cool0";
				device_type = "cpucore";
			};

			gpufreq_cool {
				dyn_coeff = <0x8c>;
				node_name = "bifrost";
				device_type = "gpufreq";
			};
		};

		cpucore_cool0 {
			#cooling-cells = <0x2>;
		};
	};

	thermal-zones {

		soc_thermal {
			polling-delay = <0x3e8>;
			polling-delay-passive = <0x64>;
			sustainable-power = <0x488>;
			thermal-sensors = <0x48 0x0>;

			trips {

				trip-point@0 {
					temperature = <0x14c08>;
					hysteresis = <0x1388>;
					type = "passive";
				};

				trip-point@1 {
					temperature = <0x17318>;
					hysteresis = <0x1388>;
					type = "passive";
					phandle = <0x49>;
				};

				trip-point@2 {
					temperature = <0x19a28>;
					hysteresis = <0x3e8>;
					type = "critical";
				};
			};

			cooling-maps {

				cpufreq_cooling_map {
					trip = <0x49>;
					cooling-device = <0x4a 0x0 0x8>;
					contribution = <0x400>;
				};

				gpufreq_cooling_map {
					trip = <0x49>;
					cooling-device = <0x4b 0x0 0x3>;
					contribution = <0x400>;
				};
			};
		};
	};

	ion_dev {
		compatible = "amlogic, ion_dev";
		memory-region = <0x4c>;
	};

	meson_uvm {
		compatible = "amlogic, meson_uvm";
		status = "okay";
	};

	meson_videotunnel {
		compatible = "amlogic, meson_videotunnel";
		status = "okay";
	};

	fb {
		compatible = "amlogic, fb-s4";
		memory-region = <0x4d>;
		status = "disabled";
		interrupts = <0x0 0xc5 0x1 0x0 0xd7 0x1>;
		interrupt-names = "viu-vsync", "rdma";
		display_mode_default = "1080p60hz";
		scale_mode = <0x1>;
		display_size_default = <0x780 0x438 0x780 0x870 0x20>;
		mem_size = <0x800000 0x1980000 0x100000>;
		logo_addr = "0x7f800000";
		mem_alloc = <0x0>;
		pxp_mode = <0x0>;
	};

	meson-irblaster@fe08410c {
		compatible = "amlogic, meson_irblaster";
		status = "okay";
		reg = <0x0 0xfe08410c 0x0 0x10>;
		#irblaster-cells = <0x2>;
		interrupts = <0x0 0x17 0x1>;
	};

	vdin0 {
		compatible = "amlogic, vdin-s4";
		dev_name = "vdin0";
		status = "okay";
		reserve-iomap = "true";
		flag_cma = <0x0>;
		interrupts = <0x0 0xd2 0x1>;
		rdma-irq = <0x2>;
		clocks = <0xb 0xb 0xb 0xd4>;
		clock-names = "fclk_div5", "cts_vdin_meas_clk";
		vdin_id = <0x0>;
		cma_size = <0x14>;
		tv_bit_mode = <0x1>;
	};

	vdin1 {
		compatible = "amlogic, vdin-s4";
		dev_name = "vdin1";
		status = "okay";
		reserve-iomap = "true";
		flag_cma = <0x0>;
		interrupts = <0x0 0xd4 0x1>;
		rdma-irq = <0x4>;
		vdin_id = <0x1>;
		memory-region = <0x4e>;
		tv_bit_mode = <0x1>;
	};

	meson-amvideom {
		compatible = "amlogic, amvideom-s4";
		dev_name = "amvideom";
		status = "okay";
		interrupts = <0x0 0xc5 0x1>;
		interrupt-names = "vsync";
	};

	video_composer {
		compatible = "amlogic, video_composer";
		dev_name = "video_composer";
		status = "okay";
	};

	vpu_security {
		compatible = "amlogic, meson-s4, vpu_security";
		dev_name = "amlogic-vpu-security";
		status = "okay";
		interrupts = <0x0 0xdc 0x1>;
		interrupt-names = "vpu_security";
	};

	ge2d {
		compatible = "amlogic, ge2d-s4";
		status = "okay";
		interrupts = <0x0 0xd9 0x1>;
		interrupt-names = "ge2d";
		clocks = <0xb 0xd0 0xb 0x121 0xb 0xd1>;
		clock-names = "clk_vapb_0", "clk_ge2d", "clk_ge2d_gate";
		reg = <0x0 0xff040000 0x0 0x100>;
		power-domains = <0x25 0x4>;
	};

	aml_bt {
		compatible = "amlogic, aml-bt";
		status = "okay";
		reset-gpios = <0x1b 0x41 0x0>;
		btwakeup-gpios = <0x1b 0x42 0x0>;
		hostwake-gpios = <0x1b 0x43 0x0>;
	};

	aml_wifi {
		compatible = "amlogic, aml-wifi";
		status = "okay";
		irq_trigger_type = "GPIO_IRQ_LOW";
		pwm_config = <0x4f>;
		interrupt-gpios = <0x1b 0x37 0x0>;
		power_on-gpios = <0x1b 0x36 0x0>;
	};

	wifi_pwm_conf {
		phandle = <0x4f>;

		pwm_channel1_conf {
			pwms = <0x50 0x0 0x774d 0x0>;
			duty-cycle = <0x3ba6>;
			times = <0x7>;
		};

		pwm_channel2_conf {
			pwms = <0x50 0x2 0x7724 0x0>;
			duty-cycle = <0x3b92>;
			times = <0xa>;
		};
	};

	state_led {
		compatible = "amlogic,state-led-aocpu";
		status = "disabled";
	};

	efuse {
		compatible = "amlogic, efuse";
		reg = <0x0 0xfe440040 0x0 0x4>;
		secureboot_mask = <0xc00>;
		mem_size = <0x100000>;
		read_cmd = <0x82000030>;
		write_cmd = <0x82000031>;
		get_max_cmd = <0x82000033>;
		mem_in_base_cmd = <0x82000020>;
		mem_out_base_cmd = <0x82000021>;
		efuse_pattern_size = <0x600>;
		key = <0x51>;
		clock-names = "efuse_clk";
		status = "okay";
	};

	efusekey {
		keynum = <0x4>;
		key0 = <0x52>;
		key1 = <0x53>;
		key2 = <0x54>;
		key3 = <0x55>;
		phandle = <0x51>;

		key_0 {
			keyname = "mac";
			offset = <0x0>;
			size = <0x6>;
			phandle = <0x52>;
		};

		key_1 {
			keyname = "mac_bt";
			offset = <0x6>;
			size = <0x6>;
			phandle = <0x53>;
		};

		key_2 {
			keyname = "mac_wifi";
			offset = <0xc>;
			size = <0x6>;
			phandle = <0x54>;
		};

		key_3 {
			keyname = "usid";
			offset = <0x12>;
			size = <0x10>;
			phandle = <0x55>;
		};
	};

	drm-amhdmitx {
		status = "okay";
		hdcp = "disabled";
		compatible = "amlogic, drm-amhdmitx";
		dev_name = "meson-amhdmitx";
		interrupts = <0x0 0xcc 0x1>;

		ports {

			port {
				#address-cells = <0x1>;
				#size-cells = <0x0>;

				endpoint@0 {
					reg = <0x0>;
					remote-endpoint = <0x56>;
					phandle = <0x59>;
				};
			};
		};
	};

	drm-amcvbsout {
		status = "okay";
		compatible = "amlogic, drm-cvbsout";
		dev_name = "meson-amcvbsout";

		ports {

			port {
				#address-cells = <0x1>;
				#size-cells = <0x0>;

				endpoint@0 {
					reg = <0x0>;
					remote-endpoint = <0x57>;
					phandle = <0x5a>;
				};
			};
		};
	};

	drm-lcd {
		status = "disabled";
		compatible = "amlogic, drm-lcd";
		dev_name = "meson-lcd";

		ports {

			port {
				#address-cells = <0x1>;
				#size-cells = <0x0>;

				endpoint@0 {
					reg = <0x0>;
					remote-endpoint = <0x58>;
					phandle = <0x5b>;
				};
			};
		};
	};

	drm-vpu@0xff900000 {
		status = "okay";
		compatible = "amlogic, meson-s4-vpu";
		memory-region = <0x4d>;
		osd_ver = [04];
		reg = <0x0 0xff900000 0x0 0x40000 0x0 0xff63c000 0x0 0x2000 0x0 0xff638000 0x0 0x2000>;
		reg-names = "base", "hhi", "dmc";
		interrupts = <0x0 0xc5 0x1>;
		interrupt-names = "viu-vsync";
		clocks = <0xb 0xc9>;
		clock-names = "vpu_clkc";
		dma-coherent;
		logo_addr = "0x7f800000";

		port {
			#address-cells = <0x1>;
			#size-cells = <0x0>;
			phandle = <0x5c>;

			endpoint@0 {
				reg = <0x0>;
				remote-endpoint = <0x59>;
				phandle = <0x56>;
			};

			endpoint@1 {
				reg = <0x1>;
				remote-endpoint = <0x5a>;
				phandle = <0x57>;
			};

			endpoint@2 {
				reg = <0x2>;
				remote-endpoint = <0x5b>;
				phandle = <0x58>;
			};
		};
	};

	drm-subsystem {
		status = "okay";
		compatible = "amlogic, drm-subsystem";
		ports = <0x5c>;
		fbdev_sizes = <0x780 0x438 0x780 0x870 0x20>;

		vpu_topology {

			vpu_blocks {

				block@0 {
					id = [00];
					index = [00];
					type = [00];
					block_name = "osd1_block";
					num_in_links = [00];
					num_out_links = [01];
					out_links = <0x0 0x5d>;
					phandle = <0x5f>;
				};

				block@1 {
					id = [01];
					index = [01];
					type = [00];
					block_name = "osd2_block";
					num_in_links = [00];
					num_out_links = [01];
					out_links = <0x0 0x5e>;
					phandle = <0x61>;
				};

				block@3 {
					id = [03];
					index = [00];
					type = [01];
					block_name = "afbc_osd1_block";
					num_in_links = [01];
					in_links = <0x0 0x5f>;
					num_out_links = [01];
					out_links = <0x0 0x60>;
					phandle = <0x5d>;
				};

				block@4 {
					id = [04];
					index = [01];
					type = [01];
					block_name = "afbc_osd2_block";
					num_in_links = [01];
					in_links = <0x0 0x61>;
					num_out_links = [01];
					out_links = <0x0 0x62>;
					phandle = <0x5e>;
				};

				block@6 {
					id = [06];
					index = [00];
					type = [02];
					block_name = "scaler_osd1_block";
					num_in_links = [01];
					in_links = <0x0 0x63>;
					num_out_links = [01];
					out_links = <0x0 0x64>;
					phandle = <0x65>;
				};

				block@7 {
					id = [07];
					index = [01];
					type = [02];
					block_name = "scaler_osd2_block";
					num_in_links = [01];
					in_links = <0x0 0x5e>;
					num_out_links = [01];
					out_links = <0x2 0x60>;
					phandle = <0x62>;
				};

				block@9 {
					id = [09];
					block_name = "osd_blend_block";
					type = [03];
					num_in_links = [02];
					in_links = <0x0 0x5d 0x0 0x62>;
					num_out_links = [02];
					out_links = <0x0 0x63 0x1 0x64>;
					phandle = <0x60>;
				};

				block@10 {
					id = [0a];
					block_name = "osd1_hdr_dolby_block";
					type = [04];
					num_in_links = [01];
					in_links = <0x0 0x60>;
					num_out_links = [01];
					out_links = <0x0 0x65>;
					phandle = <0x63>;
				};

				block@12 {
					id = [0b];
					block_name = "vpp_postblend_block";
					type = [06];
					num_in_links = [02];
					in_links = <0x0 0x65 0x1 0x60>;
					num_out_links = <0x0>;
					phandle = <0x64>;
				};

				block@13 {
					id = [0c];
					index = [00];
					type = [07];
					block_name = "video1_block";
					num_in_links = [00];
					num_out_links = [00];
				};

				block@14 {
					id = [0d];
					index = [01];
					type = [07];
					block_name = "video2_block";
					num_in_links = [00];
					num_out_links = [00];
				};
			};
		};

		vpu_hw_para@0 {
			osd_ver = [02];
			afbc_type = [02];
			has_deband = [01];
			has_lut = [01];
			has_rdma = [01];
			osd_fifo_len = [40];
			vpp_fifo_len = <0xfff>;
		};
	};

	firmware {

		android {
			compatible = "android,firmware";

			vbmeta {
				compatible = "android,vbmeta";
				parts = "vbmeta,boot,oem,vbmeta_system";
				by_name_prefix = "/dev/block";
			};
		};
	};

	partitions {
		parts = <0x19>;
		part-0 = <0x66>;
		part-1 = <0x67>;
		part-2 = <0x68>;
		part-3 = <0x69>;
		part-4 = <0x6a>;
		part-5 = <0x6b>;
		part-6 = <0x6c>;
		part-7 = <0x6d>;
		part-8 = <0x6e>;
		part-9 = <0x6f>;
		part-10 = <0x70>;
		part-11 = <0x71>;
		part-12 = <0x72>;
		part-13 = <0x73>;
		part-14 = <0x74>;
		part-15 = <0x75>;
		part-16 = <0x76>;
		part-17 = <0x77>;
		part-18 = <0x78>;
		part-19 = <0x79>;
		part-20 = <0x7a>;
		part-21 = <0x7b>;
		part-22 = <0x7c>;
		part-23 = <0x7d>;
		part-24 = <0x7e>;

		frp {
			pname = "frp";
			size = <0x0 0x200000>;
			mask = <0x1>;
			phandle = <0x66>;
		};

		factory {
			pname = "factory";
			size = <0x0 0x800000>;
			mask = <0x11>;
			phandle = <0x67>;
		};

		vendor_boot_a {
			pname = "vendor_boot_a";
			size = <0x0 0x1800000>;
			mask = <0x1>;
			phandle = <0x68>;
		};

		vendor_boot_b {
			pname = "vendor_boot_b";
			size = <0x0 0x1800000>;
			mask = <0x1>;
			phandle = <0x69>;
		};

		tee {
			pname = "tee";
			size = <0x0 0x2000000>;
			mask = <0x1>;
			phandle = <0x6a>;
		};

		logo {
			pname = "logo";
			size = <0x0 0x800000>;
			mask = <0x1>;
			phandle = <0x6b>;
		};

		misc {
			pname = "misc";
			size = <0x0 0x200000>;
			mask = <0x1>;
			phandle = <0x6c>;
		};

		dtbo_a {
			pname = "dtbo_a";
			size = <0x0 0x200000>;
			mask = <0x1>;
			phandle = <0x6d>;
		};

		dtbo_b {
			pname = "dtbo_b";
			size = <0x0 0x200000>;
			mask = <0x1>;
			phandle = <0x6e>;
		};

		cri_data {
			pname = "cri_data";
			size = <0x0 0x800000>;
			mask = <0x2>;
			phandle = <0x6f>;
		};

		rsv {
			pname = "rsv";
			size = <0x0 0x1000000>;
			mask = <0x1>;
			phandle = <0x77>;
		};

		metadata {
			pname = "metadata";
			size = <0x0 0x1000000>;
			mask = <0x1>;
			phandle = <0x78>;
		};

		vbmeta_a {
			pname = "vbmeta_a";
			size = <0x0 0x200000>;
			mask = <0x1>;
			phandle = <0x79>;
		};

		vbmeta_b {
			pname = "vbmeta_b";
			size = <0x0 0x200000>;
			mask = <0x1>;
			phandle = <0x7a>;
		};

		vbmeta_system_a {
			pname = "vbmeta_system_a";
			size = <0x0 0x200000>;
			mask = <0x1>;
			phandle = <0x7b>;
		};

		vbmeta_system_b {
			pname = "vbmeta_system_b";
			size = <0x0 0x200000>;
			mask = <0x1>;
			phandle = <0x7c>;
		};

		param {
			pname = "param";
			size = <0x0 0x1000000>;
			mask = <0x2>;
			phandle = <0x70>;
		};

		odm_ext_a {
			pname = "odm_ext_a";
			size = <0x0 0x1000000>;
			mask = <0x1>;
			phandle = <0x71>;
		};

		odm_ext_b {
			pname = "odm_ext_b";
			size = <0x0 0x1000000>;
			mask = <0x1>;
			phandle = <0x72>;
		};

		oem_a {
			pname = "oem_a";
			size = <0x0 0x2000000>;
			mask = <0x1>;
			phandle = <0x73>;
		};

		oem_b {
			pname = "oem_b";
			size = <0x0 0x2000000>;
			mask = <0x1>;
			phandle = <0x74>;
		};

		boot_a {
			pname = "boot_a";
			size = <0x0 0x4000000>;
			mask = <0x1>;
			phandle = <0x75>;
		};

		boot_b {
			pname = "boot_b";
			size = <0x0 0x4000000>;
			mask = <0x1>;
			phandle = <0x76>;
		};

		super {
			pname = "super";
			size = <0x0 0x80000000>;
			mask = <0x1>;
			phandle = <0x7d>;
		};

		userdata {
			pname = "userdata";
			size = <0xffffffff 0xffffffff>;
			mask = <0x4>;
			phandle = <0x7e>;
		};
	};

	aliases {
		serial0 = "/soc/apb4@fe000000/serial@7a000";
		serial1 = "/soc/serial@fe078000";
		serial2 = "/soc/serial@fe07c000";
		serial3 = "/soc/serial@fe07e000";
		serial4 = "/soc/serial@fe080000";
		i2c0 = "/soc/apb4@fe000000/i2c@66000";
		i2c1 = "/soc/apb4@fe000000/i2c@68000";
		i2c2 = "/soc/apb4@fe000000/i2c@6a000";
		i2c3 = "/soc/apb4@fe000000/i2c@6c000";
		i2c4 = "/soc/apb4@fe000000/i2c@6e000";
		spi0 = "/soc/apb4@fe000000/spi@56000";
		spi1 = "/soc/apb4@fe000000/spi@50000";
		tsensor0 = "/p_tsensor@fe020000";
	};

	memory@00000000 {
		device_type = "memory";
		linux,usable-memory = <0x0 0x0 0x0 0x80000000>;
	};

	reserved-memory {
		#address-cells = <0x2>;
		#size-cells = <0x2>;
		ranges;

		ramoops@0x07400000 {
			compatible = "ramoops";
			reg = <0x0 0x7400000 0x0 0x100000>;
			record-size = <0x20000>;
			console-size = <0x40000>;
			ftrace-size = <0x80000>;
			pmsg-size = <0x20000>;
		};

		linux,secmon {
			compatible = "shared-dma-pool";
			reusable;
			size = <0x0 0x3400000>;
			alignment = <0x0 0x400000>;
			alloc-ranges = <0x0 0x5000000 0x0 0x3400000>;
			phandle = <0x13>;
		};

		linux,meson-fb {
			compatible = "shared-dma-pool";
			reusable;
			size = <0x0 0x800000>;
			alignment = <0x0 0x400000>;
			alloc-ranges = <0x0 0x7f800000 0x0 0x800000>;
			phandle = <0x4d>;
		};

		linux,ion-dev {
			compatible = "shared-dma-pool";
			reusable;
			size = <0x0 0x8000000>;
			alignment = <0x0 0x400000>;
			phandle = <0x4c>;
		};

		linux,di_cma {
			compatible = "shared-dma-pool";
			reusable;
			alignment = <0x0 0x400000>;
		};

		linux,ppmgr {
			compatible = "shared-dma-pool";
			size = <0x0>;
			phandle = <0x84>;
		};

		linux,codec_mm_cma {
			compatible = "shared-dma-pool";
			reusable;
			size = <0x0 0x1b000000>;
			alignment = <0x0 0x400000>;
			linux,contiguous-region;
			phandle = <0x7f>;
		};

		linux,codec_mm_reserved {
			compatible = "amlogic, codec-mm-reserved";
			size = <0x0 0x0>;
			alignment = <0x0 0x100000>;
			phandle = <0x80>;
		};

		linux,vdin1_cma {
			compatible = "shared-dma-pool";
			reusable;
			size = <0x0 0x1400000>;
			alignment = <0x0 0x400000>;
			phandle = <0x4e>;
		};
	};

	codec_mm {
		compatible = "amlogic, codec, mm";
		memory-region = <0x7f 0x80>;
		dev_name = "codec_mm";
		status = "okay";
	};

	amdolby_vision {
		compatible = "amlogic, dolby_vision_sc2";
		dev_name = "aml_amdolby_vision_driver";
		status = "disabled";
		tv_mode = <0x0>;
	};

	cvbsout {
		compatible = "amlogic, cvbsout-s4";
		status = "okay";
		clk_path = <0x0>;
		performance = <0x1bf0 0x9 0x1b56 0x333 0x1b12 0x8080 0x1b05 0xfd 0x1c59 0xf850 0xffff 0x0>;
		performance_sarft = <0x1bf0 0x9 0x1b56 0x333 0x1b12 0x0 0x1b05 0x9 0x1c59 0xfc48 0xffff 0x0>;
		performance_revB_telecom = <0x1bf0 0x9 0x1b56 0x546 0x1b12 0x8080 0x1b05 0x9 0x1c59 0xf850 0xffff 0x0>;
	};

	dvb-extern {
		compatible = "amlogic, dvb-extern";
		dev_name = "dvb-extern";
		status = "disabled";
		dvb_power_gpio = <0x1b 0x49 0x0>;
		dvb_power_value = <0x1>;
		dvb_power_dir = <0x0>;
		fe_num = <0x3>;
		fe0_demod = "internal";
		fe0_tuner0 = <0x0>;
		fe1_demod = "internal";
		fe1_tuner0 = <0x1>;
		fe2_demod = "cxd2856";
		fe2_i2c_adap_id = <0x81>;
		fe2_demod_i2c_addr = <0xd8>;
		fe2_reset_value = <0x0>;
		fe2_reset_gpio = <0x1b 0x48 0x0>;
		fe2_reset_dir = <0x0>;
		fe2_ant_poweron_value = <0x0>;
		fe2_ant_power_gpio = <0x1b 0x2d 0x0>;
		fe2_ts = <0x0>;
		fe2_tuner1 = <0x3>;
		tuner_num = <0x4>;
		tuner0_name = "r836_tuner";
		tuner0_i2c_adap = <0x82>;
		tuner0_i2c_addr = <0x1a>;
		tuner0_xtal = <0x0>;
		tuner0_xtal_mode = <0x0>;
		tuner0_xtal_cap = <0x10>;
		tuner0_lt_out = <0x1>;
		tuner1_name = "r836_tuner";
		tuner1_i2c_adap = <0x82>;
		tuner1_i2c_addr = <0x3a>;
		tuner1_xtal = <0x0>;
		tuner1_xtal_mode = <0x0>;
		tuner1_xtal_cap = <0x10>;
		tuner1_lt_out = <0x1>;
		tuner2_name = "av2018_tuner";
		tuner2_i2c_adap = <0x82>;
		tuner2_i2c_addr = <0xc4>;
		tuner2_lt_out = <0x1>;
		tuner3_name = "av2018_tuner";
		tuner3_lt_out = <0x1>;
	};

	dvb-demux {
		compatible = "amlogic sc2, dvb-demux";
		dev_name = "dvb-demux";
		status = "disabled";
		reg = <0x0 0xfe000000 0x0 0x480000>;
		dmxdev_num = <0x4>;
		tsn_from = "demod";
		ts0_sid = <0x20>;
		ts0 = "serial-4wire";
		ts0_control = <0x0>;
		ts0_invert = <0x0>;
		ts1_sid = <0x21>;
		ts1 = "parallel";
		ts1_control = <0x0>;
		ts1_invert = <0x0>;
		ts2_sid = <0x22>;
		ts2 = "parallel";
		ts2_control = <0x0>;
		ts2_invert = <0x0>;
		pinctrl-names = "s_ts0";
		pinctrl-0 = <0x83>;
	};

	ionvideo {
		compatible = "amlogic, ionvideo";
		dev_name = "ionvideo";
		status = "okay";
	};

	amlvideo2_0 {
		compatible = "amlogic, amlvideo2";
		dev_name = "amlvideo2";
		status = "okay";
		amlvideo2_id = <0x0>;
		cma_mode = <0x1>;
	};

	amlvideo2_1 {
		compatible = "amlogic, amlvideo2";
		dev_name = "amlvideo2";
		status = "okay";
		amlvideo2_id = <0x1>;
		cma_mode = <0x1>;
	};

	ppmgr {
		compatible = "amlogic, ppmgr";
		memory-region = <0x84>;
		dev_name = "ppmgr";
		status = "okay";
	};

	amlvecm {
		compatible = "amlogic, vecm";
		dev_name = "aml_vecm";
		status = "okay";
		gamma_en = <0x0>;
		wb_en = <0x0>;
		cm_en = <0x0>;
		tx_op_color_primary = <0x0>;
	};

	multi-di {
		compatible = "amlogic, dim-s4";
		status = "okay";
		flag_cma = <0x4>;
		interrupts = <0x0 0xcb 0x1 0x0 0xca 0x1>;
		interrupt-names = "pre_irq", "post_irq";
		clocks = <0xb 0xc2 0xb 0xbd>;
		clock-names = "vpu_clkb", "vpu_mux";
		clock-range = <0x14e 0x29b>;
		buffer-size = <0x3e2c40>;
		post-wr-support = <0x1>;
		nr10bit-support = <0x1>;
		nrds-enable = <0x1>;
		pps-enable = <0x1>;
	};

	provisionkey {
		compatible = "amlogic, provisionkey";
		status = "disabled";
		key-permit-default = "write";

		KEY_PROVISION_XXX {
		};
	};

	unifykey {
		compatible = "amlogic,unifykey";
		status = "ok";
		unifykey-num = <0x13>;
		unifykey-index-0 = <0x85>;
		unifykey-index-1 = <0x86>;
		unifykey-index-2 = <0x87>;
		unifykey-index-3 = <0x88>;
		unifykey-index-4 = <0x89>;
		unifykey-index-5 = <0x8a>;
		unifykey-index-6 = <0x8b>;
		unifykey-index-7 = <0x8c>;
		unifykey-index-8 = <0x8d>;
		unifykey-index-9 = <0x8e>;
		unifykey-index-10 = <0x8f>;
		unifykey-index-11 = <0x90>;
		unifykey-index-12 = <0x91>;
		unifykey-index-13 = <0x92>;
		unifykey-index-14 = <0x93>;
		unifykey-index-15 = <0x94>;
		unifykey-index-16 = <0x95>;
		unifykey-index-17 = <0x96>;
		unifykey-index-18 = <0x97>;

		key_0 {
			key-name = "usid";
			key-device = "normal";
			key-permit = "read", "write", "del";
			phandle = <0x85>;
		};

		key_1 {
			key-name = "mac";
			key-device = "normal";
			key-permit = "read", "write", "del";
			phandle = <0x86>;
		};

		key_2 {
			key-name = "hdcp";
			key-device = "secure";
			key-type = "sha1";
			key-permit = "read", "write", "del";
			phandle = <0x87>;
		};

		key_3 {
			key-name = "secure_boot_set";
			key-device = "efuse";
			key-permit = "write";
			phandle = <0x88>;
		};

		key_4 {
			key-name = "mac_bt";
			key-device = "normal";
			key-permit = "read", "write", "del";
			key-type = "mac";
			phandle = <0x89>;
		};

		key_5 {
			key-name = "mac_wifi";
			key-device = "normal";
			key-permit = "read", "write", "del";
			key-type = "mac";
			phandle = <0x8a>;
		};

		key_6 {
			key-name = "hdcp2_tx";
			key-device = "normal";
			key-permit = "read", "write", "del";
			phandle = <0x8b>;
		};

		key_7 {
			key-name = "hdcp2_rx";
			key-device = "normal";
			key-permit = "read", "write", "del";
			phandle = <0x8c>;
		};

		key_8 {
			key-name = "widevinekeybox";
			key-device = "secure";
			key-permit = "read", "write", "del";
			phandle = <0x8d>;
		};

		key_9 {
			key-name = "deviceid";
			key-device = "normal";
			key-permit = "read", "write", "del";
			phandle = <0x8e>;
		};

		key_10 {
			key-name = "hdcp22_fw_private";
			key-device = "secure";
			key-permit = "read", "write", "del";
			phandle = <0x8f>;
		};

		key_11 {
			key-name = "PlayReadykeybox25";
			key-device = "secure";
			key-permit = "read", "write", "del";
			phandle = <0x90>;
		};

		key_12 {
			key-name = "prpubkeybox";
			key-device = "secure";
			key-permit = "read", "write", "del";
			phandle = <0x91>;
		};

		key_13 {
			key-name = "prprivkeybox";
			key-device = "secure";
			key-permit = "read", "write", "del";
			phandle = <0x92>;
		};

		key_14 {
			key-name = "attestationkeybox";
			key-device = "secure";
			key-permit = "read", "write", "del";
			phandle = <0x93>;
		};

		key_15 {
			key-name = "region_code";
			key-device = "normal";
			key-permit = "read", "write", "del";
			phandle = <0x94>;
		};

		key_16 {
			key-name = "netflix_mgkid";
			key-device = "secure";
			key-permit = "read", "write", "del";
			phandle = <0x95>;
		};

		key_17 {
			key-name = "attestationdevidbox";
			key-device = "secure";
			key-permit = "read", "write", "del";
			phandle = <0x96>;
		};

		key_18 {
			key-name = "oemkey";
			key-device = "normal";
			key-permit = "read", "write", "del";
			phandle = <0x97>;
		};
	};

	auge_sound {
		compatible = "amlogic, auge-sound-card";
		aml-audio-card,name = "AML-AUGESOUND";
		avout_mute-gpios = <0x1b 0x29 0x0>;
		spk_mute-gpios = <0x1b 0x2c 0x1>;

		aml-audio-card,dai-link@0 {
			format = "dsp_a";
			mclk-fs = <0x200>;
			bitclock-master = <0x98>;
			frame-master = <0x98>;
			suffix-name = "alsaPORT-pcm";

			cpu {
				sound-dai = <0x98>;
				dai-tdm-slot-tx-mask = <0x1>;
				dai-tdm-slot-rx-mask = <0x1>;
				dai-tdm-slot-num = <0x2>;
				dai-tdm-slot-width = <0x10>;
				system-clock-frequency = <0x3e800>;
			};

			codec {
				sound-dai = <0x99>;
			};
		};

		aml-audio-card,dai-link@1 {
			format = "i2s";
			mclk-fs = <0x100>;
			bitclock-master = <0x9a>;
			frame-master = <0x9a>;
			suffix-name = "alsaPORT-i2s2hdmi";

			cpu {
				sound-dai = <0x9a>;
				dai-tdm-slot-tx-mask = <0x1 0x1>;
				dai-tdm-slot-rx-mask = <0x1 0x1>;
				dai-tdm-slot-num = <0x2>;
				dai-tdm-slot-width = <0x20>;
				system-clock-frequency = <0xbb8000>;
			};

			codec {
				sound-dai = <0x99>;
			};
		};

		aml-audio-card,dai-link@2 {
			format = "i2s";
			mclk-fs = <0x100>;
			bitclock-master = <0x9b>;
			frame-master = <0x9b>;
			suffix-name = "alsaPORT-i2s";

			cpu {
				sound-dai = <0x9b>;
				dai-tdm-slot-tx-mask = <0x1 0x1>;
				dai-tdm-slot-rx-mask = <0x1 0x1>;
				dai-tdm-slot-num = <0x2>;
				dai-tdm-slot-width = <0x20>;
				system-clock-frequency = <0xbb8000>;
			};

			codec {
				sound-dai = <0x9c>;
			};
		};

		aml-audio-card,dai-link@3 {
			mclk-fs = <0x40>;
			suffix-name = "alsaPORT-pdm-builtinmic";

			cpu {
				sound-dai = <0x9d>;
			};

			codec {
				sound-dai = <0x99>;
			};
		};

		aml-audio-card,dai-link@4 {
			mclk-fs = <0x80>;
			suffix-name = "alsaPORT-spdif";

			cpu {
				sound-dai = <0x9e>;
				system-clock-frequency = <0x5dc000>;
			};

			codec {
				sound-dai = <0x99>;
			};
		};

		aml-audio-card,dai-link@5 {
			mclk-fs = <0x80>;
			continuous-clock;
			suffix-name = "alsaPORT-spdifb";

			cpu {
				sound-dai = <0x9f>;
				system-clock-frequency = <0x5dc000>;
			};

			codec {
				sound-dai = <0x99>;
			};
		};

		aml-audio-card,dai-link@6 {
			mclk-fs = <0x100>;
			continuous-clock;
			suffix-name = "alsaPORT-loopback";

			cpu {
				sound-dai = <0xa0>;
				system-clock-frequency = <0xbb8000>;
			};

			codec {
				sound-dai = <0x99>;
			};
		};
	};

	picdec {
		compatible = "amlogic, picdec";
		status = "okay";
	};

	locker {
		compatible = "amlogic, audiolocker";
		clock-names = "lock_out", "lock_in", "out_src", "in_src", "out_calc", "in_ref";
		interrupts = <0x0 0x1 0x1>;
		interrupt-names = "irq";
		frequency = <0x2ebae40>;
		dividor = <0x31>;
		status = "disabled";
	};

	adc_keypad {
		compatible = "amlogic, adc_keypad";
		status = "disabled";
		key_name = "standby", "vol+", "vol-";
		key_num = <0x3>;
		io-channels = <0xa1 0x0>;
		io-channel-names = "key-chan-0";
		key_chan = <0x0 0x0 0x0>;
		key_code = <0x74 0x73 0x72>;
		key_val = <0x14 0x38e 0x276>;
		key_tolerance = <0x28 0x28 0x28>;
	};

	gpio_keypad {
		compatible = "amlogic, gpio_keypad";
		status = "disabled";
		scan_period = <0x14>;
		key_num = <0x1>;
		key_name = "bluetooth";
		key_code = <0x258>;
		key-gpios = <0x1b 0x1a 0x0>;
		detect_mode = <0x0>;
	};
};
